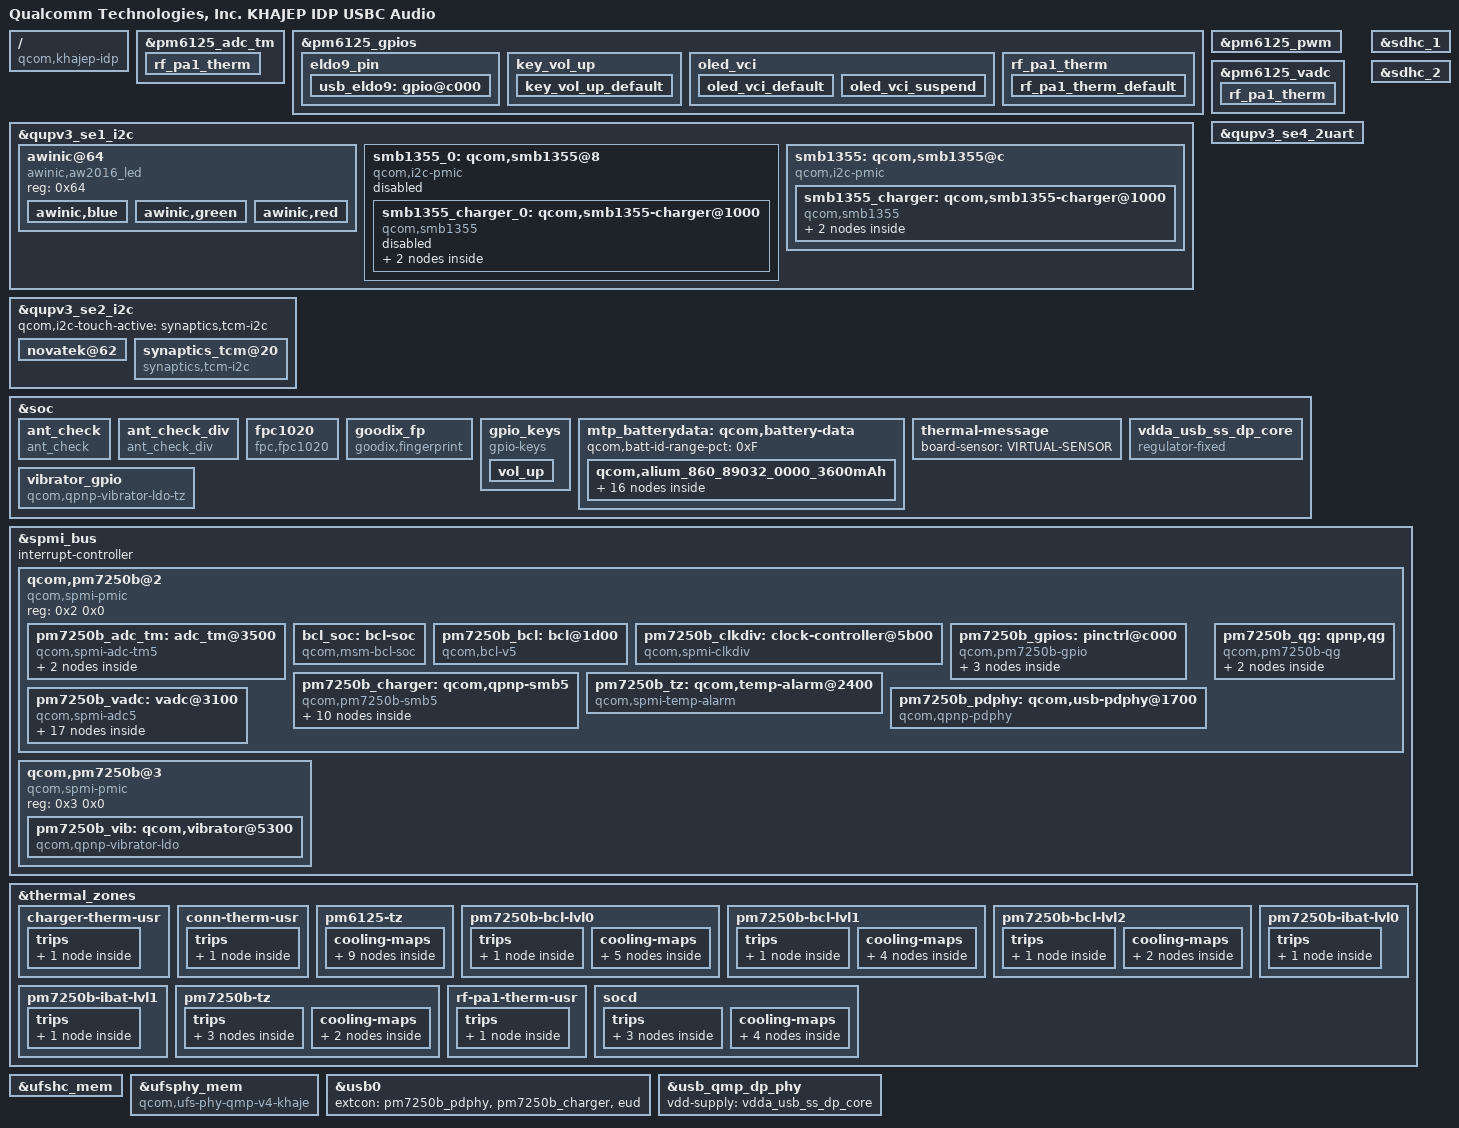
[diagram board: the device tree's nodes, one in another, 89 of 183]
/dts-v1/;
// version: 17
// last_comp_version: 16
// boot_cpuid_phys: 0x0

/ {
    compatible = "qcom,khajep-idp", "qcom,khajep", "qcom,idp";
    model = "Qualcomm Technologies, Inc. KHAJEP IDP USBC Audio";
    qcom,board-id = <0x1010022 0x0>;
    qcom,msm-id = <0x231 0x10000>;
    qcom,pmic-id = <0x2D 0x2E 0x0 0x0>;
};

&pm6125_adc_tm {
    status = "ok";
    rf_pa1_therm {
        io-channels = <&pm6125_vadc 0x55>;
        qcom,hw-settle-time-us = <0xC8>;
        qcom,ratiometric;
        reg = <0x3>;
    };
};

&pm6125_gpios {
    eldo9_pin {
        usb_eldo9: gpio@c000 {
            bias-disable;
            function = "normal";
            output-high;
            pins = "gpio1";
            power-source = <0x0>;
            qcom,drive-strength = <0x2>;
        };
    };
    key_vol_up {
        key_vol_up_default: key_vol_up_default {
            bias-pull-up;
            function = "normal";
            input-enable;
            pins = "gpio5";
            power-source = <0x0>;
        };
    };
    oled_vci {
        oled_vci_default: oled_vci_default {
            bias-disable;
            function = "normal";
            input-disable;
            output-high;
            pins = "gpio9";
            power-source = <0x0>;
            qcom,drive-strength = <0x2>;
        };
        oled_vci_suspend: oled_vci_suspend {
            bias-disable;
            function = "normal";
            input-disable;
            output-low;
            pins = "gpio9";
            power-source = <0x0>;
            qcom,drive-strength = <0x2>;
        };
    };
    rf_pa1_therm {
        rf_pa1_therm_default: rf_pa1_therm_default {
            bias-high-impedance;
            pins = "gpio7";
        };
    };
};

&pm6125_pwm {
    status = "ok";
};

&pm6125_vadc {
    pinctrl-0 = <&camera_therm_default &emmc_therm_default &rf_pa1_therm_default>;
    rf_pa1_therm {
        label = "rf_pa1_therm";
        qcom,hw-settle-time = <0xC8>;
        qcom,pre-scaling = <0x1 0x1>;
        qcom,ratiometric;
        reg = <0x55>;
    };
};

&qupv3_se1_i2c {
    status = "ok";
    awinic@64 {
        compatible = "awinic,aw2016_led";
        reg = <0x64>;
        awinic,blue {
            awinic,fall-time-ms = <0x6>;
            awinic,hold-time-ms = <0x0>;
            awinic,id = <0x2>;
            awinic,imax = <0x2>;
            awinic,led-current = <0x3>;
            awinic,max-brightness = <0xFF>;
            awinic,name = "blue";
            awinic,off-time-ms = <0x4>;
            awinic,rise-time-ms = <0x6>;
        };
        awinic,green {
            awinic,fall-time-ms = <0x6>;
            awinic,hold-time-ms = <0x0>;
            awinic,id = <0x1>;
            awinic,imax = <0x2>;
            awinic,led-current = <0x3>;
            awinic,max-brightness = <0xFF>;
            awinic,name = "green";
            awinic,off-time-ms = <0x4>;
            awinic,rise-time-ms = <0x6>;
        };
        awinic,red {
            awinic,fall-time-ms = <0x6>;
            awinic,hold-time-ms = <0x0>;
            awinic,id = <0x0>;
            awinic,imax = <0x2>;
            awinic,led-current = <0x3>;
            awinic,max-brightness = <0xFF>;
            awinic,name = "red";
            awinic,off-time-ms = <0x4>;
            awinic,rise-time-ms = <0x6>;
        };
    };
    smb1355_0: qcom,smb1355@8 {
        #address-cells = <0x1>;
        #interrupt-cells = <0x3>;
        #size-cells = <0x0>;
        compatible = "qcom,i2c-pmic";
        interrupt-controller;
        interrupt-parent = <&spmi_bus>;
        interrupt_names = "smb1355_0";
        interrupts = <0x0 0xD1 0x0 0x8>;
        qcom,periph-map = <0x10 0x12 0x13 0x16>;
        reg = <0x8>;
        status = "disabled";
        smb1355_charger_0: qcom,smb1355-charger@1000 {
            #address-cells = <0x1>;
            #size-cells = <0x1>;
            compatible = "qcom,smb1355";
            interrupt-parent = <&smb1355_0>;
            reg = <0x1000>;
            status = "disabled";
            qcom,chgr-misc@1600 {
                interrupt-names = "wdog-bark", "temperature-change";
                interrupts = <0x16 0x1 0x1 0x16 0x6 0x1>;
                reg = <0x1600>;
            };
            qcom,chgr@1000 {
                interrupt-names = "chg-state-change";
                interrupts = <0x10 0x1 0x1>;
                reg = <0x1000>;
            };
        };
    };
    smb1355: qcom,smb1355@c {
        #address-cells = <0x1>;
        #interrupt-cells = <0x3>;
        #size-cells = <0x0>;
        compatible = "qcom,i2c-pmic";
        interrupt-controller;
        interrupt-parent = <&spmi_bus>;
        interrupt_names = "smb1355";
        interrupts = <0x2 0xC5 0x0 0x8>;
        pinctrl-0 = <&pm7250b_smb_int_default>;
        pinctrl-names = "default";
        qcom,periph-map = <0x10 0x12 0x13 0x16>;
        reg = <0xC>;
        status = "ok";
        smb1355_charger: qcom,smb1355-charger@1000 {
            #address-cells = <0x1>;
            #size-cells = <0x1>;
            compatible = "qcom,smb1355";
            interrupt-parent = <&smb1355>;
            qcom,hw-die-temp-mitigation;
            qcom,parallel-mode = <0x1>;
            reg = <0x1000>;
            status = "ok";
            qcom,chgr-misc@1600 {
                interrupt-names = "wdog-bark", "temperature-change";
                interrupts = <0x16 0x1 0x1 0x16 0x6 0x1>;
                reg = <0x1600>;
            };
            qcom,chgr@1000 {
                interrupt-names = "chg-state-change";
                interrupts = <0x10 0x1 0x1>;
                reg = <0x1000>;
            };
        };
    };
};

&qupv3_se2_i2c {
    qcom,i2c-touch-active = "synaptics,tcm-i2c";
    status = "okay";
    novatek@62 {
        interrupt-parent = <&tlmm>;
        interrupts = <0x50 0x2008>;
        novatek,irq-gpio = <&tlmm 0x50 0x2008>;
        novatek,reset-gpio = <&tlmm 0x56 0x0>;
        pinctrl-0 = <&ts_int_active &ts_reset_active>;
        pinctrl-1 = <&ts_int_suspend &ts_reset_suspend>;
        pinctrl-2 = <&ts_release>;
        pinctrl-names = "pmx_ts_active", "pmx_ts_suspend", "pmx_ts_release";
        reg = <0x62>;
        status = "ok";
    };
    synaptics_tcm@20 {
        compatible = "synaptics,tcm-i2c";
        interrupt-parent = <&tlmm>;
        interrupts = <0x50 0x2008>;
        pinctrl-0 = <&ts_int_active &ts_reset_active>;
        pinctrl-1 = <&ts_int_suspend &ts_reset_suspend>;
        pinctrl-2 = <&ts_release>;
        pinctrl-names = "pmx_ts_active", "pmx_ts_suspend", "pmx_ts_release";
        reg = <0x20>;
        synaptics,extend_report;
        synaptics,firmware-name = "synaptics_firmware_k.img";
        synaptics,irq-gpio = <&tlmm 0x50 0x2008>;
        synaptics,irq-on-state = <0x0>;
        synaptics,power-delay-ms = <0xC8>;
        synaptics,reset-active-ms = <0x14>;
        synaptics,reset-delay-ms = <0xC8>;
        synaptics,reset-gpio = <&tlmm 0x56 0x0>;
        synaptics,reset-on-state = <0x0>;
        synaptics,ubl-i2c-addr = <0x20>;
    };
};

&qupv3_se4_2uart {
    status = "ok";
};

&sdhc_1 {
    pinctrl-0 = <&sdc1_on>;
    pinctrl-1 = <&sdc1_off>;
    pinctrl-names = "default", "sleep";
    qcom,vdd-current-level = <0x0 0x8B290>;
    qcom,vdd-io-always-on;
    qcom,vdd-io-current-level = <0x0 0x4F588>;
    qcom,vdd-io-lpm-sup;
    qcom,vdd-io-voltage-level = <0x1B7740 0x1B7740>;
    qcom,vdd-voltage-level = <0x2D2A80 0x2D2A80>;
    status = "ok";
    vdd-io-supply = <&L11A>;
    vdd-supply = <&L24A>;
};

&sdhc_2 {
    cd-gpios = <&tlmm 0x58 0x1>;
    pinctrl-0 = <&sdc2_on>;
    pinctrl-1 = <&sdc2_off>;
    pinctrl-names = "default", "sleep";
    qcom,vdd-current-level = <0x0 0xC3500>;
    qcom,vdd-io-bias-current-level = <0x0 0x1770>;
    qcom,vdd-io-bias-voltage-level = <0x132A40 0x132A40>;
    qcom,vdd-io-current-level = <0x0 0x55F0>;
    qcom,vdd-io-voltage-level = <0x1B7740 0x2D2A80>;
    qcom,vdd-voltage-level = <0x2D2A80 0x2D2A80>;
    status = "ok";
    vdd-io-bias-supply = <&L7A>;
    vdd-io-supply = <&L5A>;
    vdd-supply = <&L22A>;
};

&soc {
    ant_check {
        ant_check_gpio = <&tlmm 0x6B 0x0>;
        compatible = "ant_check";
        interrupt-parent = <&tlmm>;
        pinctrl-0 = <&ant_check_default>;
        pinctrl-names = "default";
    };
    ant_check_div {
        ant_check_div_gpio = <&tlmm 0x19 0x0>;
        compatible = "ant_check_div";
        interrupt-parent = <&tlmm>;
        pinctrl-0 = <&ant_check_div_default>;
        pinctrl-names = "default";
    };
    fpc1020 {
        compatible = "fpc,fpc1020";
        fpc,enable-on-boot;
        fpc,gpio_irq = <&tlmm 0x53 0x0>;
        fpc,gpio_rst = <&tlmm 0x68 0x0>;
        fpc,gpio_vdd_for_plsensor = <&tlmm 0x41 0x0>;
        interrupt-parent = <&tlmm>;
        interrupts = <0x53 0x0>;
        pinctrl-0 = <&msm_gpio_104>;
        pinctrl-1 = <&msm_gpio_104_output_high>;
        pinctrl-2 = <&msm_gpio_83>;
        pinctrl-names = "fpc1020_reset_reset", "fpc1020_reset_active", "fpc1020_irq_active";
        status = "ok";
        vcc_spi-supply = <&pm6125_l9>;
        vdd_ana-supply = <&pm6125_l9>;
        vdd_io-supply = <&pm6125_l9>;
    };
    goodix_fp {
        compatible = "goodix,fingerprint";
        fp-gpio-irq = <&tlmm 0x53 0x0>;
        fp-gpio-pwr = <&tlmm 0x41 0x0>;
        fp-gpio-reset = <&tlmm 0x68 0x0>;
        interrupt = <0x53 0x0>;
        interrupt-parent = <&tlmm>;
        pinctrl-0 = <&msm_gpio_104>;
        pinctrl-1 = <&msm_gpio_104_output_high>;
        pinctrl-2 = <&msm_gpio_65>;
        pinctrl-3 = <&msm_gpio_65_output_high>;
        pinctrl-names = "goodix_reset_outputlow", "goodix_reset_outputhigh", "goodix_pwr_outputlow", "goodix_pwr_outputhigh";
        status = "okay";
        vcc_ana_supply = <&pm6125_l9>;
        vcc_spi_supply = <&pm6125_l9>;
        vdd_io-supply = <&pm6125_l9>;
    };
    gpio_keys {
        compatible = "gpio-keys";
        label = "gpio-keys";
        pinctrl-0 = <&key_vol_up_default>;
        pinctrl-names = "default";
        vol_up {
            debounce-interval = <0xF>;
            gpio-key,wakeup;
            gpios = <&pm6125_gpios 0x5 0x1>;
            label = "volume_up";
            linux,can-disable;
            linux,code = <0x73>;
            linux,input-type = <0x1>;
        };
    };
    mtp_batterydata: qcom,battery-data {
        qcom,batt-id-range-pct = <0xF>;
        qcom,alium_860_89032_0000_3600mAh {
            qcom,batt-id-kohm = <0x6B>;
            qcom,battery-beta = <0x109A>;
            qcom,battery-therm-kohm = <0x64>;
            qcom,battery-type = "Alium_860_89032_0000_3600mAh_Jun15th2018";
            qcom,fastchg-current-ma = <0x1518>;
            qcom,fg-cc-cv-threshold-uv = <0x423920>;
            qcom,jeita-fcc-ranges = <0x0 0x32 0x2625A0 0x33 0x190 0x5265C0 0x191 0x1C2 0x2625A0>;
            qcom,jeita-fv-ranges = <0x0 0x32 0x40D990 0x33 0x190 0x426030 0x191 0x1C2 0x40D990>;
            qcom,jeita-hard-thresholds = <0x58CD 0x20B8>;
            qcom,jeita-soft-fcc-ua = <0x2625A0 0x2625A0>;
            qcom,jeita-soft-fv-uv = <0x40D990 0x40D990>;
            qcom,jeita-soft-hys-thresholds = <0x4F5E 0x2943>;
            qcom,jeita-soft-thresholds = <0x5314 0x25E3>;
            qcom,max-voltage-uv = <0x426030>;
            qcom,ocv-based-step-chg;
            qcom,qg-batt-profile-ver = <0x64>;
            qcom,step-chg-ranges = <0x36EE80 0x39FBC0 0x5265C0 0x39FBC1 0x419CE0 0x36EE80 0x419CE1 0x426030 0x2625A0>;
            qcom,fcc1-temp-lut {
                qcom,lut-col-legend = <0x0 0xA 0x19 0x28 0x32>;
                qcom,lut-data = <0xD62 0xDBF 0xDFD 0xE1D 0xE2E>;
            };
            qcom,fcc2-temp-lut {
                qcom,lut-col-legend = <0xFFFFFFF6 0x0 0xA 0x19 0x28 0x32>;
                qcom,lut-data = <0xDDA 0xDF8 0xE02 0xE04 0xDFF 0xDFF>;
            };
            qcom,pc-temp-v1-lut {
                qcom,lut-col-legend = <0x0 0xA 0x19 0x28 0x32>;
                qcom,lut-data = <0xA846 0xA903 0xA965 0xA982 0xA987 0xA757 0xA82C 0xA88B 0xA8B2 0xA8BC 0xA671 0xA747 0xA7A8 0xA7D4 0xA7E5 0xA598 0xA65F 0xA6C5 0xA6F2 0xA707 0xA4CA 0xA582 0xA5E5 0xA611 0xA627 0xA3FF 0xA4AF 0xA508 0xA531 0xA546 0xA330 0xA3E1 0xA430 0xA452 0xA465 0xA25D 0xA311 0xA35C 0xA377 0xA387 0xA1A0 0xA23E 0xA287 0xA29E 0xA2AD 0xA10A 0xA17A 0xA1B1 0xA1C4 0xA1D2 0xA07E 0xA0E5 0xA0F6 0xA0F5 0xA0FC 0x9FA9 0xA061 0xA067 0xA048 0xA036 0x9E4B 0x9F9A 0x9FD6 0x9FAE 0x9F81 0x9CDB 0x9E3D 0x9EE8 0x9EE6 0x9EBF 0x9BED 0x9CD1 0x9D85 0x9DC6 0x9DD7 0x9B4D 0x9BF5 0x9C67 0x9CB4 0x9CF4 0x9AD6 0x9B65 0x9BD6 0x9C18 0x9C4A 0x9A75 0x9AF5 0x9B63 0x9BAA 0x9BC5 0x9A1F 0x9A9B 0x9ADE 0x9B13 0x9B23 0x99C4 0x9A41 0x9A3F 0x9A2D 0x9A41 0x9962 0x99C6 0x998A 0x9943 0x9959 0x98FD 0x992A 0x98B8 0x9892 0x98A0 0x9894 0x9882 0x97F4 0x9800 0x9807 0x982B 0x97C6 0x976F 0x9780 0x9781 0x97CB 0x9713 0x970F 0x970C 0x970C 0x9775 0x9697 0x96B5 0x96A2 0x96A2 0x9724 0x963E 0x965A 0x9642 0x963E 0x96DB 0x95FA 0x9603 0x95E9 0x95E1 0x9698 0x95C7 0x95B7 0x9598 0x958B 0x965B 0x959D 0x9571 0x954E 0x953B 0x9627 0x9575 0x9533 0x950C 0x94F4 0x95F8 0x9550 0x94FE 0x94D1 0x94B3 0x95CC 0x952E 0x94CF 0x949B 0x947A 0x95A2 0x9511 0x94A4 0x9465 0x9440 0x9579 0x94F7 0x947F 0x9432 0x9407 0x954F 0x94D6 0x9458 0x93FE 0x93CC 0x9525 0x94B2 0x942F 0x93C6 0x938B 0x94F0 0x9484 0x9402 0x938B 0x9345 0x94A6 0x943E 0x93BF 0x9343 0x92F7 0x944C 0x93DA 0x935F 0x92ED 0x92A2 0x93E6 0x936C 0x92F1 0x9288 0x923F 0x936B 0x92F1 0x9276 0x920E 0x91C6 0x92E1 0x926F 0x91F1 0x9188 0x9141 0x9248 0x91EA 0x9165 0x90FF 0x90BC 0x91CF 0x9176 0x9100 0x909B 0x905B 0x9179 0x9129 0x90C1 0x9060 0x9022 0x9159 0x910E 0x90AB 0x904F 0x9011 0x913E 0x90F9 0x909A 0x903F 0x9001 0x911A 0x90DE 0x907F 0x9020 0x8FDD 0x90AC 0x9070 0x8FF7 0x8F74 0x8F1A 0x8F68 0x8F1C 0x8E9E 0x8E14 0x8DB6 0x8D9D 0x8D55 0x8CD8 0x8C4C 0x8BEB 0x8B59 0x8B10 0x8A94 0x8A02 0x899F 0x8849 0x87FB 0x877D 0x86E5 0x867D 0x836C 0x8325 0x82AA 0x8209 0x8197 0x7530 0x7530 0x7530 0x7530 0x7530>;
                qcom,lut-row-legend = <0x2710 0x2648 0x2580 0x24B8 0x23F0 0x2328 0x2260 0x2198 0x20D0 0x2008 0x1F40 0x1E78 0x1DB0 0x1CE8 0x1C20 0x1B58 0x1A90 0x19C8 0x1900 0x1838 0x1770 0x16A8 0x15E0 0x1518 0x1450 0x1388 0x12C0 0x11F8 0x1130 0x1068 0xFA0 0xED8 0xE10 0xD48 0xC80 0xBB8 0xAF0 0xA28 0x960 0x898 0x7D0 0x708 0x640 0x578 0x4B0 0x3E8 0x384 0x320 0x2BC 0x258 0x1F4 0x190 0x12C 0xC8 0x64 0x0>;
            };
            qcom,pc-temp-v2-lut {
                qcom,lut-col-legend = <0xFFFFFFF6 0x0 0xA 0x19 0x28 0x32>;
                qcom,lut-data = <0xA98D 0xA97E 0xA974 0xA960 0xA92E 0xA910 0xA7FB 0xA83A 0xA854 0xA856 0xA82F 0xA819 0xA6A3 0xA712 0xA747 0xA757 0xA738 0xA728 0xA594 0xA609 0xA64D 0xA665 0xA64A 0xA63C 0xA4C7 0xA51D 0xA566 0xA581 0xA565 0xA558 0xA3F4 0xA43E 0xA489 0xA4A2 0xA484 0xA478 0xA2AF 0xA364 0xA3B3 0xA3C8 0xA3A5 0xA397 0xA162 0xA292 0xA2E4 0xA2F3 0xA2CA 0xA2B9 0xA11A 0xA1C1 0xA210 0xA21B 0xA1EF 0xA1DE 0xA14F 0xA0EA 0xA131 0xA139 0xA110 0xA103 0xA17A 0xA03C 0xA071 0xA077 0xA047 0xA035 0xA046 0x9FD6 0x9FF5 0x9FF5 0x9FB3 0x9F87 0x9D6D 0x9F7F 0x9F85 0x9F81 0x9F2B 0x9EE2 0x9B88 0x9EAB 0x9EA9 0x9EAD 0x9E5E 0x9E1A 0x9A81 0x9C78 0x9CDE 0x9D1E 0x9D16 0x9D22 0x99B8 0x9A96 0x9B46 0x9BD5 0x9BFE 0x9C3F 0x9913 0x99E8 0x9A78 0x9B4D 0x9B70 0x9B9C 0x9887 0x9977 0x99DF 0x9AEB 0x9B04 0x9B0E 0x97F7 0x98F2 0x9948 0x9A53 0x9A64 0x9A58 0x975C 0x9856 0x98B5 0x9965 0x9971 0x9967 0x96C8 0x97B8 0x9827 0x987F 0x9885 0x9883 0x9649 0x9720 0x9799 0x97D3 0x97D8 0x97D6 0x95D8 0x968D 0x9711 0x9743 0x9748 0x9745 0x957D 0x9608 0x9697 0x96C6 0x96CB 0x96C8 0x9533 0x9591 0x9629 0x9658 0x965C 0x9658 0x94F4 0x952A 0x95C3 0x95F3 0x95F6 0x95F1 0x94BC 0x94D6 0x9565 0x9595 0x9598 0x9592 0x948A 0x9491 0x950E 0x953E 0x9540 0x9538 0x9458 0x9459 0x94BD 0x94F0 0x94EF 0x94E6 0x9429 0x942B 0x9471 0x94AA 0x94A5 0x949B 0x93FA 0x9403 0x942C 0x9467 0x9461 0x9456 0x93CB 0x93DC 0x93ED 0x9426 0x9422 0x9418 0x939A 0x93B7 0x93B6 0x93E7 0x93E7 0x93DD 0x9366 0x9390 0x9384 0x93A6 0x93A1 0x9392 0x9330 0x9367 0x935A 0x9364 0x9348 0x932B 0x92F5 0x933C 0x9330 0x9322 0x92EA 0x92BD 0x92B6 0x9309 0x9301 0x92E2 0x9296 0x925D 0x9274 0x92CE 0x92CF 0x92A2 0x9248 0x9208 0x922D 0x9289 0x9294 0x925E 0x91FE 0x91BC 0x91E4 0x9235 0x924A 0x9214 0x91B6 0x9173 0x919A 0x91D4 0x91F2 0x91C0 0x9166 0x9124 0x9151 0x916D 0x918D 0x9158 0x9101 0x90C0 0x910A 0x9104 0x9119 0x90DA 0x9085 0x9045 0x90BE 0x90A5 0x90A4 0x9064 0x9011 0x8FD4 0x9066 0x9055 0x9058 0x9026 0x8FDE 0x8FA3 0x8FF1 0x9009 0x9027 0x900B 0x8FC1 0x8F87 0x8FA0 0x8FD7 0x9010 0x8FF6 0x8FB0 0x8F76 0x8F3A 0x8F9B 0x8FF2 0x8FD7 0x8F94 0x8F5B 0x8E9D 0x8F3C 0x8FA7 0x8F84 0x8F3F 0x8EFC 0x8DBC 0x8E73 0x8ECD 0x8E86 0x8E46 0x8DF2 0x8C72 0x8D0B 0x8D41 0x8CE7 0x8CA5 0x8C4F 0x8A95 0x8B0D 0x8B2A 0x8AD3 0x8A9A 0x8A45 0x87F8 0x8865 0x887D 0x881C 0x87EC 0x879D 0x841A 0x8496 0x84D3 0x8488 0x847E 0x8426 0x7ECA 0x7F24 0x801B 0x8028 0x7F97 0x7EF0 0x6FCB 0x6E6E 0x6D71 0x6D74 0x6D50 0x6D1A>;
                qcom,lut-row-legend = <0x2710 0x2648 0x2580 0x24B8 0x23F0 0x2328 0x2260 0x2198 0x20D0 0x2008 0x1F40 0x1E78 0x1DB0 0x1CE8 0x1C20 0x1B58 0x1A90 0x19C8 0x1900 0x1838 0x1770 0x16A8 0x15E0 0x1518 0x1450 0x1388 0x12C0 0x11F8 0x1130 0x1068 0xFA0 0xED8 0xE10 0xD48 0xC80 0xBB8 0xAF0 0xA28 0x960 0x898 0x7D0 0x708 0x640 0x578 0x4B0 0x3E8 0x384 0x320 0x2BC 0x258 0x1F4 0x190 0x12C 0xC8 0x64 0x0>;
            };
            qcom,pc-temp-y1-lut {
                qcom,lut-col-legend = <0xFFFFFFF6 0x0 0xA 0x19 0x28 0x32>;
                qcom,lut-data = <0x1DAE 0x1A6C 0x17B7 0x1540 0x1467 0x143B 0x1DB4 0x1A6F 0x17C3 0x153F 0x1466 0x143D 0x1DC0 0x1A74 0x17CA 0x153E 0x1466 0x143E 0x1DCD 0x1A7A 0x17CE 0x153C 0x1466 0x1440 0x1DD8 0x1A7E 0x17D0 0x153B 0x1467 0x1441 0x1DDD 0x1A80 0x17D0 0x153A 0x1467 0x1443 0x1DDC 0x1A80 0x17CC 0x153A 0x1468 0x1443 0x1DDA 0x1A80 0x17C6 0x153A 0x146A 0x1444 0x1DD3 0x1A7D 0x17C5 0x153B 0x146C 0x1445 0x1DBC 0x1A76 0x17C8 0x153C 0x146D 0x1446 0x1DAA 0x1A70 0x17CA 0x153D 0x146F 0x1448 0x1DB3 0x1A6E 0x17C6 0x153D 0x1470 0x1449 0x1DC8 0x1A6F 0x17C0 0x153D 0x1472 0x144B 0x1DDC 0x1A74 0x17C1 0x153E 0x1474 0x144D 0x1DF4 0x1A85 0x17D0 0x1545 0x1479 0x1452 0x1E03 0x1A97 0x17DB 0x154D 0x147C 0x1454 0x1DFA 0x1AA4 0x17DF 0x154F 0x147C 0x1455 0x1DE7 0x1AAF 0x17E3 0x1552 0x147D 0x1455 0x1DD8 0x1AB0 0x17E4 0x1554 0x147E 0x1456 0x1DCA 0x1AA1 0x17E2 0x1555 0x1480 0x1459 0x1DC3 0x1A95 0x17E2 0x1558 0x1483 0x145C 0x1DD6 0x1A97 0x17ED 0x155C 0x1487 0x1460 0x1DF9 0x1A9F 0x17FB 0x1560 0x148B 0x1463 0x1E01 0x1AA5 0x17FD 0x1565 0x148E 0x1467 0x1E00 0x1AA8 0x17F8 0x1569 0x1491 0x146A 0x1E04 0x1AAC 0x17F7 0x156D 0x1493 0x146E 0x1E09 0x1AB8 0x1800 0x1571 0x1496 0x1472 0x1E0C 0x1ACC 0x180B 0x1576 0x149A 0x1475 0x1E0A 0x1AD7 0x180E 0x157B 0x149D 0x1478 0x1DF8 0x1ADC 0x1812 0x1581 0x14A0 0x147A 0x1DE0 0x1ADE 0x1817 0x1586 0x14A3 0x147D 0x1DD9 0x1ADB 0x181B 0x158B 0x14A7 0x1480 0x1DDB 0x1AD7 0x181F 0x1590 0x14AA 0x1484 0x1DDD 0x1AD7 0x1820 0x1593 0x14AD 0x1487 0x1DE1 0x1AD5 0x1821 0x1596 0x14B0 0x1489 0x1DE8 0x1AD3 0x1823 0x1599 0x14B2 0x148B 0x1DF7 0x1ADF 0x1827 0x159B 0x14B4 0x148C 0x1E0A 0x1AEF 0x182C 0x159D 0x14B5 0x148D 0x1E0D 0x1AEF 0x1831 0x159E 0x14B5 0x148E 0x1DFF 0x1AE3 0x1835 0x159F 0x14B6 0x148E 0x1DF5 0x1ADF 0x183A 0x15A1 0x14B7 0x148F 0x1DF6 0x1AE5 0x1841 0x15A5 0x14B9 0x1491 0x1DF6 0x1AEB 0x184C 0x15A8 0x14BA 0x1492 0x1DF6 0x1AF2 0x1849 0x15AA 0x14BB 0x1493 0x1DFA 0x1AF8 0x1850 0x15AF 0x14BE 0x1495 0x1E04 0x1B0B 0x1850 0x15B1 0x14BE 0x1496 0x1E09 0x1B08 0x1859 0x15B4 0x14BE 0x1496 0x1E26 0x1B0E 0x1863 0x15B4 0x14BE 0x1496 0x1E37 0x1B0B 0x186B 0x15B6 0x14BF 0x1496 0x1E2C 0x1B1E 0x1867 0x15B9 0x14C2 0x1498 0x1E29 0x1B3F 0x1879 0x15C2 0x14C5 0x149B 0x1E38 0x1B5B 0x1895 0x15D1 0x14CC 0x14A0 0x1E61 0x1B5F 0x18A8 0x15E4 0x14D3 0x14A6 0x1EB6 0x1B7E 0x18CA 0x15F7 0x14DC 0x14AC 0x1EB6 0x1B7E 0x18CA 0x15F7 0x14DC 0x14AC 0x1EB6 0x1B7E 0x18CA 0x15F7 0x14DC 0x14AC>;
                qcom,lut-row-legend = <0x2710 0x2648 0x2580 0x24B8 0x23F0 0x2328 0x2260 0x2198 0x20D0 0x2008 0x1F40 0x1E78 0x1DB0 0x1CE8 0x1C20 0x1B58 0x1A90 0x19C8 0x1900 0x1838 0x1770 0x16A8 0x15E0 0x1518 0x1450 0x1388 0x12C0 0x11F8 0x1130 0x1068 0xFA0 0xED8 0xE10 0xD48 0xC80 0xBB8 0xAF0 0xA28 0x960 0x898 0x7D0 0x708 0x640 0x578 0x4B0 0x3E8 0x384 0x320 0x2BC 0x258 0x1F4 0x190 0x12C 0xC8 0x64 0x0>;
            };
            qcom,pc-temp-y2-lut {
                qcom,lut-col-legend = <0xFFFFFFF6 0x0 0xA 0x19 0x28 0x32>;
                qcom,lut-data = <0x25D6 0x28A1 0x29B8 0x2B2A 0x2B60 0x2C89 0x2638 0x287F 0x299B 0x2B15 0x2B62 0x2C51 0x2674 0x286A 0x297A 0x2AFB 0x2B61 0x2BFC 0x2693 0x285F 0x2959 0x2ADE 0x2B5E 0x2BA2 0x269F 0x285B 0x293D 0x2ABD 0x2B58 0x2B5A 0x26A2 0x285A 0x292B 0x2A9A 0x2B51 0x2B3C 0x266C 0x2867 0x2922 0x2A6D 0x2B48 0x2B43 0x260B 0x287D 0x291B 0x2A3F 0x2B3B 0x2B4E 0x25F2 0x2878 0x2916 0x2A29 0x2B28 0x2B4D 0x25FE 0x283E 0x2912 0x2A1C 0x2B09 0x2B3A 0x2615 0x2814 0x2910 0x2A13 0x2AE5 0x2B24 0x2698 0x2862 0x291A 0x2A04 0x2AB6 0x2AFB 0x2784 0x28EA 0x2933 0x29F0 0x2A85 0x2AC3 0x27BA 0x2909 0x295A 0x29F2 0x2A7A 0x2ABC 0x26D8 0x28F6 0x29A8 0x2A1D 0x2A90 0x2AF0 0x2601 0x28E9 0x29E0 0x2A53 0x2AB0 0x2B19 0x25E5 0x28FF 0x29FA 0x2A91 0x2AEC 0x2B1B 0x25DE 0x2924 0x2A0E 0x2AD0 0x2B33 0x2B18 0x25D8 0x292D 0x2A1D 0x2AEF 0x2B47 0x2B23 0x25D2 0x292C 0x2A2B 0x2AFC 0x2B48 0x2B59 0x25CD 0x2929 0x2A36 0x2B0A 0x2B4A 0x2B9B 0x25CA 0x28F3 0x2A3F 0x2B29 0x2B78 0x2BD9 0x25C8 0x2849 0x2A48 0x2B54 0x2BC0 0x2C13 0x25C6 0x27D1 0x2A4B 0x2B74 0x2BE2 0x2C3D 0x25C3 0x275F 0x2A50 0x2B8F 0x2BF6 0x2C5C 0x25C0 0x271C 0x2A54 0x2BA1 0x2C07 0x2C71 0x25BF 0x270E 0x2A52 0x2BAC 0x2C19 0x2C83 0x25BE 0x2700 0x2A4A 0x2BB0 0x2C2D 0x2C96 0x25BD 0x26ED 0x2A46 0x2BA7 0x2C35 0x2CB5 0x25BC 0x26D4 0x2A44 0x2B8E 0x2C41 0x2CEC 0x25BB 0x26B9 0x2A3F 0x2B80 0x2C4D 0x2D11 0x25BB 0x26A1 0x29E9 0x2B83 0x2C40 0x2D02 0x25BA 0x268B 0x294E 0x2B8F 0x2C2F 0x2CDA 0x25B9 0x2672 0x290B 0x2B9C 0x2C33 0x2CCA 0x25B8 0x2655 0x28FA 0x2B99 0x2C39 0x2CD1 0x25B8 0x263A 0x28EE 0x2B84 0x2C35 0x2CD6 0x25B7 0x2622 0x28E6 0x2B68 0x2C34 0x2CDC 0x25B7 0x2604 0x290B 0x2B59 0x2C39 0x2CE8 0x25B6 0x25EC 0x293C 0x2B5F 0x2C3B 0x2CE7 0x25B6 0x25DE 0x291D 0x2B60 0x2C36 0x2CD1 0x25B6 0x25D4 0x28BA 0x2B5F 0x2C32 0x2CC5 0x25B6 0x25CB 0x289C 0x2B62 0x2C34 0x2CCC 0x25B6 0x25C4 0x28A6 0x2B5D 0x2C32 0x2CCF 0x25B5 0x25BE 0x281B 0x2B46 0x2C13 0x2CC8 0x25B5 0x25BB 0x27D7 0x2B34 0x2C13 0x2CB0 0x25B5 0x25BB 0x27C4 0x2B11 0x2C20 0x2C82 0x25B5 0x25BA 0x2810 0x2B0D 0x2C0A 0x2C51 0x25B5 0x25B9 0x2851 0x2B23 0x2BE8 0x2C48 0x25B5 0x25B8 0x2853 0x2B28 0x2BEF 0x2C50 0x25B4 0x25B8 0x2837 0x2AE6 0x2C1E 0x2C3A 0x25B4 0x25B6 0x2800 0x2ACC 0x2BF7 0x2BFD 0x25B4 0x25B5 0x27BC 0x2AA1 0x2B7E 0x2BA7 0x25B4 0x25B4 0x2786 0x2A49 0x2B0F 0x2B35 0x25B2 0x25B4 0x2773 0x2A1C 0x2A4F 0x2A4A 0x25B2 0x25B4 0x2773 0x2A1C 0x2A4F 0x2A4A 0x25B2 0x25B4 0x2773 0x2A1C 0x2A4F 0x2A4A>;
                qcom,lut-row-legend = <0x2710 0x2648 0x2580 0x24B8 0x23F0 0x2328 0x2260 0x2198 0x20D0 0x2008 0x1F40 0x1E78 0x1DB0 0x1CE8 0x1C20 0x1B58 0x1A90 0x19C8 0x1900 0x1838 0x1770 0x16A8 0x15E0 0x1518 0x1450 0x1388 0x12C0 0x11F8 0x1130 0x1068 0xFA0 0xED8 0xE10 0xD48 0xC80 0xBB8 0xAF0 0xA28 0x960 0x898 0x7D0 0x708 0x640 0x578 0x4B0 0x3E8 0x384 0x320 0x2BC 0x258 0x1F4 0x190 0x12C 0xC8 0x64 0x0>;
            };
            qcom,pc-temp-y3-lut {
                qcom,lut-col-legend = <0xFFFFFFF6 0x0 0xA 0x19 0x28 0x32>;
                qcom,lut-data = <0x347A 0x3456 0x3421 0x33E5 0x33E0 0x33D8 0x356B 0x345F 0x341A 0x33E4 0x33E0 0x33DA 0x35FF 0x346C 0x3416 0x33E3 0x33E0 0x33DB 0x364D 0x3479 0x3416 0x33E3 0x33E0 0x33DD 0x366B 0x3484 0x3418 0x33E3 0x33E0 0x33DE 0x3670 0x3489 0x341C 0x33E5 0x33E0 0x33DE 0x35EC 0x3489 0x3423 0x33E8 0x33E0 0x33DE 0x34FC 0x3488 0x342B 0x33ED 0x33E1 0x33DE 0x34BB 0x348B 0x342E 0x33EF 0x33E1 0x33DE 0x34BA 0x349E 0x342F 0x33F0 0x33E1 0x33DD 0x34BB 0x34AC 0x3430 0x33F0 0x33E1 0x33DD 0x34D3 0x349E 0x343D 0x33F7 0x33E4 0x33DF 0x3504 0x3481 0x3450 0x3401 0x33E9 0x33E2 0x3510 0x3471 0x3451 0x3402 0x33EA 0x33E3 0x34EC 0x3468 0x343B 0x33FE 0x33E8 0x33E2 0x34CC 0x3462 0x3427 0x33FB 0x33E6 0x33E2 0x34D0 0x345F 0x3422 0x33FD 0x33E8 0x33E2 0x34E0 0x345D 0x341F 0x3401 0x33EC 0x33E3 0x34E7 0x345A 0x341B 0x3401 0x33EC 0x33E3 0x34E9 0x3455 0x3416 0x33F9 0x33E7 0x33E0 0x34EA 0x344F 0x3411 0x33F0 0x33E3 0x33DD 0x34EC 0x3445 0x340C 0x33E8 0x33E1 0x33DC 0x34F0 0x3435 0x3407 0x33E3 0x33E0 0x33DB 0x34F5 0x3427 0x3406 0x33E2 0x33DF 0x33DB 0x3500 0x341C 0x3405 0x33E3 0x33DE 0x33DB 0x3512 0x3417 0x3405 0x33E4 0x33DE 0x33DA 0x3525 0x3418 0x3405 0x33E3 0x33DE 0x33DA 0x3539 0x341B 0x3405 0x33E3 0x33DD 0x33DA 0x354F 0x341F 0x3405 0x33E5 0x33DD 0x33DA 0x356B 0x3423 0x3405 0x33E9 0x33DD 0x33D9 0x358D 0x3428 0x3405 0x33EC 0x33DD 0x33D9 0x35B2 0x342D 0x3400 0x33ED 0x33DE 0x33D9 0x35DA 0x3434 0x33F9 0x33EC 0x33DE 0x33DA 0x360A 0x343C 0x33F6 0x33EC 0x33DF 0x33DA 0x3641 0x3449 0x33F7 0x33EA 0x33DE 0x33DA 0x3680 0x3458 0x33F8 0x33E8 0x33DE 0x33D9 0x36C1 0x3468 0x33FB 0x33E6 0x33DE 0x33D9 0x3702 0x347A 0x3402 0x33E4 0x33DD 0x33D9 0x3742 0x3490 0x3408 0x33E3 0x33DD 0x33D9 0x3781 0x34B0 0x340C 0x33E3 0x33DD 0x33D9 0x37C1 0x34DC 0x340F 0x33E3 0x33DD 0x33D9 0x3803 0x3511 0x3415 0x33E3 0x33DE 0x33DA 0x3845 0x3550 0x341E 0x33E3 0x33DE 0x33DA 0x3892 0x35A3 0x3421 0x33E4 0x33DE 0x33DA 0x38EA 0x3613 0x3429 0x33E3 0x33DE 0x33DA 0x390D 0x3642 0x3430 0x33EB 0x33DF 0x33DC 0x393F 0x363E 0x3435 0x33EC 0x33E1 0x33DD 0x395C 0x3658 0x3442 0x33F0 0x33E3 0x33E0 0x398D 0x36B9 0x3451 0x33F2 0x33E2 0x33E0 0x3A0B 0x3718 0x3452 0x33EE 0x33E1 0x33DD 0x3A97 0x37A6 0x345A 0x33F0 0x33E0 0x33DD 0x3B31 0x3888 0x346F 0x33F5 0x33E3 0x33E1 0x3C10 0x3978 0x3492 0x33F9 0x33E6 0x33E4 0x3F2C 0x3A7B 0x34CA 0x3403 0x33EA 0x33E6 0x3F2C 0x3A7B 0x34CA 0x3403 0x33EA 0x33E6 0x3F2C 0x3A7B 0x34CA 0x3403 0x33EA 0x33E6>;
                qcom,lut-row-legend = <0x2710 0x2648 0x2580 0x24B8 0x23F0 0x2328 0x2260 0x2198 0x20D0 0x2008 0x1F40 0x1E78 0x1DB0 0x1CE8 0x1C20 0x1B58 0x1A90 0x19C8 0x1900 0x1838 0x1770 0x16A8 0x15E0 0x1518 0x1450 0x1388 0x12C0 0x11F8 0x1130 0x1068 0xFA0 0xED8 0xE10 0xD48 0xC80 0xBB8 0xAF0 0xA28 0x960 0x898 0x7D0 0x708 0x640 0x578 0x4B0 0x3E8 0x384 0x320 0x2BC 0x258 0x1F4 0x190 0x12C 0xC8 0x64 0x0>;
            };
            qcom,pc-temp-y4-lut {
                qcom,lut-col-legend = <0xFFFFFFF6 0x0 0xA 0x19 0x28 0x32>;
                qcom,lut-data = <0x45B5 0x41D2 0x40F2 0x406D 0x4045 0x4044 0x452B 0x41DB 0x40EF 0x4073 0x4045 0x4042 0x44EB 0x41EB 0x40EF 0x4078 0x4047 0x4041 0x44E9 0x4200 0x40F2 0x407B 0x4048 0x4040 0x4515 0x421B 0x40F7 0x407D 0x404A 0x4040 0x4561 0x4239 0x40FE 0x407E 0x404B 0x4040 0x4627 0x4263 0x4106 0x407C 0x404D 0x4041 0x478B 0x428E 0x4111 0x407A 0x404E 0x4044 0x4914 0x42A4 0x411C 0x407A 0x4051 0x4046 0x4B24 0x42AD 0x4127 0x4081 0x4055 0x4049 0x4C74 0x42BC 0x4138 0x408C 0x405B 0x404D 0x4A3E 0x4407 0x419F 0x409E 0x4069 0x4059 0x4560 0x4626 0x4237 0x40B4 0x407D 0x4068 0x437A 0x4642 0x4251 0x40BD 0x4081 0x406C 0x4347 0x43A8 0x4203 0x40BF 0x407D 0x406B 0x432D 0x41B1 0x41AA 0x40C3 0x407B 0x406A 0x4320 0x41B5 0x416E 0x40EC 0x4091 0x407A 0x430D 0x41E2 0x413B 0x4129 0x40BA 0x4098 0x42EF 0x41ED 0x4117 0x412A 0x40C0 0x409D 0x42B4 0x41C5 0x40FA 0x40D1 0x4094 0x407D 0x4274 0x4198 0x40E3 0x4085 0x4066 0x405B 0x4249 0x4180 0x40D4 0x4078 0x4054 0x404D 0x4228 0x416E 0x40C8 0x4072 0x4049 0x4043 0x421F 0x416B 0x40C2 0x406F 0x4048 0x4042 0x4223 0x415F 0x40BE 0x406B 0x4048 0x4042 0x422B 0x414F 0x40BB 0x4069 0x4049 0x4043 0x4231 0x4143 0x40BA 0x406B 0x404B 0x4045 0x423B 0x4137 0x40BA 0x406D 0x404E 0x4048 0x4246 0x4136 0x40B9 0x406E 0x4051 0x404C 0x4252 0x4142 0x40B4 0x4070 0x4057 0x4051 0x425E 0x4154 0x40B0 0x4072 0x405E 0x4058 0x426A 0x4167 0x40B4 0x4074 0x4068 0x4063 0x4276 0x417F 0x40BD 0x4076 0x4073 0x4070 0x4283 0x4198 0x40C4 0x4074 0x4075 0x4072 0x4290 0x41B2 0x40C9 0x4069 0x4064 0x4061 0x429C 0x41CD 0x40CD 0x405E 0x404F 0x404C 0x42A8 0x41EF 0x40D2 0x405B 0x4044 0x4043 0x42B5 0x421F 0x40D8 0x4059 0x403E 0x403F 0x42C7 0x4244 0x40DC 0x405A 0x403E 0x4040 0x42E1 0x4252 0x40E9 0x405D 0x4042 0x4045 0x4308 0x425C 0x40FD 0x4060 0x4047 0x404A 0x433B 0x4262 0x410C 0x4063 0x4048 0x404B 0x437E 0x4270 0x4118 0x4064 0x4046 0x4048 0x43D3 0x4287 0x4129 0x4061 0x403D 0x403B 0x442A 0x42C2 0x4147 0x406B 0x4041 0x403E 0x441B 0x42EF 0x4160 0x4075 0x4057 0x405A 0x441E 0x4307 0x4166 0x4084 0x4070 0x4078 0x43ED 0x432A 0x4193 0x40A2 0x4099 0x40A2 0x43D0 0x436E 0x41E6 0x40BE 0x409C 0x4098 0x43E5 0x4383 0x41DE 0x409E 0x406E 0x4064 0x43F6 0x4384 0x41D8 0x409E 0x4060 0x4059 0x4411 0x43A0 0x41FB 0x40BD 0x4070 0x4067 0x4463 0x43F1 0x4266 0x40FB 0x4090 0x4085 0x470A 0x44A2 0x432D 0x41DE 0x4141 0x4118 0x470A 0x44A2 0x432D 0x41DE 0x4141 0x4118 0x470A 0x44A2 0x432D 0x41DE 0x4141 0x4118>;
                qcom,lut-row-legend = <0x2710 0x2648 0x2580 0x24B8 0x23F0 0x2328 0x2260 0x2198 0x20D0 0x2008 0x1F40 0x1E78 0x1DB0 0x1CE8 0x1C20 0x1B58 0x1A90 0x19C8 0x1900 0x1838 0x1770 0x16A8 0x15E0 0x1518 0x1450 0x1388 0x12C0 0x11F8 0x1130 0x1068 0xFA0 0xED8 0xE10 0xD48 0xC80 0xBB8 0xAF0 0xA28 0x960 0x898 0x7D0 0x708 0x640 0x578 0x4B0 0x3E8 0x384 0x320 0x2BC 0x258 0x1F4 0x190 0x12C 0xC8 0x64 0x0>;
            };
            qcom,pc-temp-y5-lut {
                qcom,lut-col-legend = <0xFFFFFFF6 0x0 0xA 0x19 0x28 0x32>;
                qcom,lut-data = <0x2208 0x348A 0x3AB0 0x3545 0x4573 0x3634 0x2208 0x34AA 0x3839 0x3326 0x4393 0x3E82 0x269F 0x34E2 0x3660 0x31DB 0x419B 0x43DA 0x2F8B 0x3522 0x3519 0x3130 0x3FBF 0x46E0 0x3428 0x3557 0x345A 0x30F0 0x3E34 0x4838 0x3590 0x3572 0x341A 0x30E7 0x3D2F 0x4884 0x30EE 0x3576 0x34B3 0x32D3 0x3CA4 0x46C7 0x2869 0x3578 0x35A4 0x35E5 0x3C3F 0x4385 0x267F 0x34B6 0x35C2 0x3648 0x3B81 0x4119 0x2A54 0x3032 0x3545 0x34D0 0x3996 0x3E92 0x2FF6 0x2CF8 0x3494 0x33CF 0x387F 0x3CE5 0x37E1 0x2FD6 0x333D 0x3525 0x3964 0x3CFD 0x4112 0x360E 0x319C 0x3768 0x3ACB 0x3DBD 0x4280 0x3A64 0x326C 0x37DC 0x3B0D 0x3DBF 0x373B 0x3DD4 0x395E 0x3745 0x3A7A 0x3CB2 0x2CF9 0x3F72 0x3ECA 0x36D1 0x3A41 0x3BB0 0x2D03 0x3EC5 0x3F83 0x384B 0x3AE8 0x3B5D 0x2EDC 0x3DC2 0x3FC3 0x3B9D 0x3C38 0x3B2B 0x2F8C 0x3D9A 0x3F92 0x3DC7 0x3E57 0x3B93 0x2F1E 0x3DF3 0x3ECF 0x3F34 0x4225 0x3E9F 0x2E5C 0x3E54 0x3DE6 0x3FC8 0x445B 0x4233 0x2D64 0x3C6D 0x3C08 0x3C17 0x4527 0x44E0 0x2C30 0x3697 0x3971 0x3578 0x4604 0x471B 0x2B6B 0x3248 0x38A0 0x33D2 0x4627 0x47FF 0x2B06 0x2F1A 0x38D8 0x353A 0x4512 0x484D 0x2AD4 0x2D6F 0x3925 0x3660 0x43D2 0x484F 0x2ADD 0x2D4C 0x3975 0x3678 0x4315 0x4790 0x2AEC 0x2D55 0x39CC 0x366C 0x4294 0x45BC 0x2AF3 0x2D44 0x3A34 0x38ED 0x427B 0x43FF 0x2B16 0x2D12 0x3B09 0x40EE 0x4270 0x426F 0x2B4E 0x2D07 0x3BA6 0x465A 0x4280 0x41AA 0x2B80 0x2D07 0x38CB 0x47E5 0x43EF 0x42BB 0x2BA9 0x2CEC 0x3382 0x48DB 0x472C 0x45F6 0x2BD0 0x2CE9 0x319E 0x48B8 0x4A98 0x495F 0x2BF8 0x2D41 0x31A4 0x45BB 0x4E8C 0x4C69 0x2C20 0x2DAA 0x31B5 0x4185 0x51DA 0x4EA9 0x2C45 0x2DD9 0x3221 0x3E14 0x52FB 0x508E 0x2C64 0x2D8A 0x34AF 0x3AEE 0x5257 0x524A 0x2C6C 0x2D32 0x3713 0x3918 0x50BC 0x5292 0x2C5A 0x2D52 0x36DE 0x38BF 0x4E90 0x50E7 0x2C45 0x2D99 0x34F7 0x3913 0x4DBC 0x4F8F 0x2C53 0x2DA9 0x354F 0x3906 0x4EA8 0x5136 0x2CB7 0x2D71 0x370B 0x3898 0x515E 0x56C7 0x2D6C 0x2D2C 0x33CD 0x3962 0x555B 0x5C52 0x2E6E 0x2CC8 0x325A 0x3610 0x4CC2 0x4EA4 0x2FC4 0x2D10 0x320A 0x3E49 0x4394 0x4373 0x30B0 0x2D1B 0x3431 0x3E08 0x42CC 0x40B6 0x322C 0x2E86 0x370E 0x4092 0x40BE 0x3F21 0x3256 0x3099 0x3915 0x3FE1 0x3E27 0x3E5B 0x322C 0x3127 0x38B1 0x3E5F 0x428D 0x410E 0x3117 0x3039 0x38E1 0x4283 0x4414 0x4431 0x2F77 0x2F18 0x37F8 0x4528 0x4741 0x4A06 0x2E6F 0x2E5E 0x37CA 0x4396 0x477B 0x4AB1 0x2B65 0x2D9D 0x3932 0x4343 0x45A6 0x476B 0x2B65 0x2D9D 0x3932 0x4343 0x45A6 0x476B 0x2B65 0x2D9D 0x3932 0x4343 0x45A6 0x476B>;
                qcom,lut-row-legend = <0x2710 0x2648 0x2580 0x24B8 0x23F0 0x2328 0x2260 0x2198 0x20D0 0x2008 0x1F40 0x1E78 0x1DB0 0x1CE8 0x1C20 0x1B58 0x1A90 0x19C8 0x1900 0x1838 0x1770 0x16A8 0x15E0 0x1518 0x1450 0x1388 0x12C0 0x11F8 0x1130 0x1068 0xFA0 0xED8 0xE10 0xD48 0xC80 0xBB8 0xAF0 0xA28 0x960 0x898 0x7D0 0x708 0x640 0x578 0x4B0 0x3E8 0x384 0x320 0x2BC 0x258 0x1F4 0x190 0x12C 0xC8 0x64 0x0>;
            };
            qcom,pc-temp-y6-lut {
                qcom,lut-col-legend = <0xFFFFFFF6 0x0 0xA 0x19 0x28 0x32>;
                qcom,lut-data = <0x1AF4 0x1607 0x1492 0x13C9 0x139D 0x1392 0x1AFB 0x160E 0x148D 0x13C8 0x139D 0x1393 0x1AFF 0x1616 0x148A 0x13C7 0x139D 0x1394 0x1AFF 0x161E 0x148A 0x13C8 0x139D 0x1395 0x1AFC 0x1626 0x148C 0x13C9 0x139E 0x1395 0x1AF7 0x162E 0x148E 0x13CA 0x139F 0x1396 0x1AC7 0x1636 0x1494 0x13CC 0x139F 0x1397 0x1A78 0x163E 0x149C 0x13CF 0x13A1 0x1397 0x1A74 0x1646 0x14A1 0x13D2 0x13A2 0x1398 0x1AFF 0x164C 0x14A3 0x13D4 0x13A3 0x1399 0x1B70 0x1657 0x14A8 0x13D7 0x13A5 0x139A 0x1AF4 0x16AC 0x14CC 0x13E2 0x13AC 0x139F 0x19D3 0x172C 0x1503 0x13EF 0x13B5 0x13A6 0x1941 0x172C 0x150B 0x13F2 0x13B7 0x13A8 0x190E 0x1670 0x14E5 0x13F1 0x13B5 0x13A7 0x18F6 0x15E2 0x14BE 0x13F0 0x13B3 0x13A7 0x18FB 0x15E4 0x14AB 0x13FD 0x13BB 0x13AC 0x1909 0x15F5 0x149C 0x1412 0x13C9 0x13B5 0x190D 0x15F9 0x148F 0x1412 0x13CB 0x13B7 0x190C 0x15ED 0x1483 0x13F3 0x13BB 0x13AB 0x190A 0x15E0 0x147A 0x13D6 0x13AB 0x139F 0x190D 0x15D6 0x1473 0x13CD 0x13A4 0x139A 0x191A 0x15CE 0x146E 0x13C8 0x13A1 0x1397 0x192C 0x15C9 0x146D 0x13C7 0x13A0 0x1397 0x1945 0x15C7 0x146E 0x13C7 0x13A0 0x1397 0x1964 0x15C6 0x146F 0x13C8 0x13A0 0x1398 0x1982 0x15CB 0x1470 0x13C9 0x13A1 0x1398 0x19A0 0x15D5 0x1473 0x13CA 0x13A2 0x1399 0x19C0 0x15E2 0x1475 0x13CC 0x13A3 0x139A 0x19E6 0x15F3 0x1476 0x13D0 0x13A5 0x139C 0x1A11 0x1607 0x1477 0x13D4 0x13A7 0x139E 0x1A3F 0x161D 0x1478 0x13D6 0x13AB 0x13A2 0x1A72 0x1638 0x1479 0x13D7 0x13AF 0x13A6 0x1AA7 0x1655 0x147B 0x13D6 0x13B0 0x13A7 0x1AE0 0x1676 0x147F 0x13D2 0x13AB 0x13A2 0x1B1C 0x169B 0x1483 0x13CE 0x13A5 0x139C 0x1B59 0x16C6 0x1488 0x13CC 0x13A2 0x139A 0x1B96 0x16F8 0x1490 0x13CB 0x13A0 0x1398 0x1BD4 0x1732 0x149A 0x13CA 0x13A0 0x1399 0x1C13 0x1772 0x14A5 0x13CB 0x13A1 0x139A 0x1C51 0x17BC 0x14B0 0x13CD 0x13A3 0x139C 0x1C90 0x1811 0x14BF 0x13CE 0x13A4 0x139D 0x1CD3 0x1875 0x14D0 0x13CF 0x13A3 0x139C 0x1D22 0x18EF 0x14E0 0x13D0 0x13A1 0x1399 0x1D80 0x1984 0x14F9 0x13D2 0x13A3 0x139A 0x1DA5 0x19B9 0x150C 0x13DB 0x13A9 0x13A3 0x1DCF 0x19C4 0x1513 0x13E1 0x13B2 0x13AD 0x1DDE 0x19E7 0x152F 0x13EC 0x13BF 0x13BB 0x1E04 0x1A57 0x155A 0x13F6 0x13C0 0x13B8 0x1E6D 0x1ABF 0x1560 0x13EB 0x13B2 0x13A7 0x1EDF 0x1B41 0x1573 0x13EE 0x13AE 0x13A5 0x1F66 0x1C0D 0x15AB 0x13FD 0x13B6 0x13AC 0x2034 0x1CDF 0x160E 0x1415 0x13C2 0x13B7 0x23C8 0x1DE5 0x16A3 0x1461 0x13F8 0x13E4 0x23C8 0x1DE5 0x16A3 0x1461 0x13F8 0x13E4 0x23C8 0x1DE5 0x16A3 0x1461 0x13F8 0x13E4>;
                qcom,lut-row-legend = <0x2710 0x2648 0x2580 0x24B8 0x23F0 0x2328 0x2260 0x2198 0x20D0 0x2008 0x1F40 0x1E78 0x1DB0 0x1CE8 0x1C20 0x1B58 0x1A90 0x19C8 0x1900 0x1838 0x1770 0x16A8 0x15E0 0x1518 0x1450 0x1388 0x12C0 0x11F8 0x1130 0x1068 0xFA0 0xED8 0xE10 0xD48 0xC80 0xBB8 0xAF0 0xA28 0x960 0x898 0x7D0 0x708 0x640 0x578 0x4B0 0x3E8 0x384 0x320 0x2BC 0x258 0x1F4 0x190 0x12C 0xC8 0x64 0x0>;
            };
            qcom,pc-temp-z1-lut {
                qcom,lut-col-legend = <0x0 0xA 0x19 0x28 0x32>;
                qcom,lut-data = <0x38D1 0x33B6 0x2F09 0x2DA0 0x2D49 0x38BB 0x337F 0x2F0D 0x2D9E 0x2D52 0x38C3 0x3376 0x2F0B 0x2DA5 0x2D5C 0x38C7 0x337E 0x2F07 0x2DA7 0x2D60 0x38D3 0x3382 0x2F03 0x2DA8 0x2D62 0x38EB 0x337D 0x2F01 0x2DA8 0x2D64 0x38FF 0x336C 0x2F02 0x2DA9 0x2D67 0x38F6 0x335E 0x2F03 0x2DAC 0x2D6A 0x38D7 0x335D 0x2F05 0x2DAE 0x2D6D 0x38B6 0x3362 0x2F09 0x2DB1 0x2D6F 0x3896 0x3360 0x2F0D 0x2DB5 0x2D72 0x3874 0x334E 0x2F0F 0x2DB8 0x2D77 0x3843 0x333C 0x2F0F 0x2DBB 0x2D7B 0x3810 0x332E 0x2F0B 0x2DBB 0x2D7C 0x37EE 0x3328 0x2F04 0x2DB9 0x2D7C 0x37D3 0x3329 0x2F01 0x2DB7 0x2D7C 0x37B6 0x3329 0x2F04 0x2DBB 0x2D7F 0x3792 0x332C 0x2F0A 0x2DC2 0x2D85 0x3772 0x3337 0x2F14 0x2DC9 0x2D8B 0x3765 0x3349 0x2F21 0x2DCE 0x2D8F 0x3763 0x335E 0x2F2C 0x2DD3 0x2D93 0x376A 0x3374 0x2F35 0x2DD8 0x2D98 0x3773 0x3384 0x2F3D 0x2DDD 0x2D9C 0x377F 0x338B 0x2F45 0x2DE1 0x2DA1 0x3787 0x3391 0x2F4D 0x2DE7 0x2DA6 0x378C 0x339A 0x2F54 0x2DEC 0x2DAA 0x378F 0x33A6 0x2F5B 0x2DF0 0x2DAF 0x3794 0x33AD 0x2F62 0x2DF4 0x2DB3 0x379F 0x33B2 0x2F69 0x2DF8 0x2DB7 0x37AF 0x33BA 0x2F6F 0x2DFC 0x2DBB 0x37C7 0x33C2 0x2F75 0x2E00 0x2DBF 0x37DE 0x33C9 0x2F7A 0x2E04 0x2DC4 0x37E6 0x33D1 0x2F80 0x2E08 0x2DC8 0x37EA 0x33DE 0x2F86 0x2E0D 0x2DCD 0x37F0 0x33F1 0x2F8E 0x2E12 0x2DD1 0x3807 0x3403 0x2F95 0x2E17 0x2DD5 0x383B 0x3415 0x2F9D 0x2E1A 0x2DD8 0x386B 0x3422 0x2FA5 0x2E1C 0x2DDA 0x3891 0x3427 0x2FAA 0x2E1F 0x2DDC 0x38B0 0x3429 0x2FAD 0x2E21 0x2DDD 0x38B2 0x342D 0x2FB1 0x2E23 0x2DDE 0x3888 0x3439 0x2FB9 0x2E25 0x2DE0 0x3873 0x3448 0x2FBF 0x2E27 0x2DE1 0x386E 0x3457 0x2FC0 0x2E28 0x2DE2 0x3861 0x3449 0x2FC4 0x2E29 0x2DE2 0x386F 0x3454 0x2FC7 0x2E2B 0x2DE2 0x3869 0x3454 0x2FC8 0x2E2B 0x2DE1 0x3868 0x345B 0x2FC9 0x2E2B 0x2DE2 0x385F 0x3457 0x2FCF 0x2E2C 0x2DE3 0x387C 0x3452 0x2FD1 0x2E30 0x2DE6 0x3886 0x346F 0x2FDB 0x2E36 0x2DEB 0x38AA 0x3476 0x2FF3 0x2E3F 0x2DF0 0x3895 0x349E 0x3007 0x2E4A 0x2DFA 0x38D0 0x34C8 0x3032 0x2E5C 0x2E06 0x38D0 0x34C8 0x3032 0x2E5C 0x2E06 0x38D0 0x34C8 0x3032 0x2E5C 0x2E06>;
                qcom,lut-row-legend = <0x2710 0x2648 0x2580 0x24B8 0x23F0 0x2328 0x2260 0x2198 0x20D0 0x2008 0x1F40 0x1E78 0x1DB0 0x1CE8 0x1C20 0x1B58 0x1A90 0x19C8 0x1900 0x1838 0x1770 0x16A8 0x15E0 0x1518 0x1450 0x1388 0x12C0 0x11F8 0x1130 0x1068 0xFA0 0xED8 0xE10 0xD48 0xC80 0xBB8 0xAF0 0xA28 0x960 0x898 0x7D0 0x708 0x640 0x578 0x4B0 0x3E8 0x384 0x320 0x2BC 0x258 0x1F4 0x190 0x12C 0xC8 0x64 0x0>;
            };
            qcom,pc-temp-z2-lut {
                qcom,lut-col-legend = <0x0 0xA 0x19 0x28 0x32>;
                qcom,lut-data = <0x2BB8 0x2632 0x2811 0x296B 0x2A9E 0x280D 0x2A3D 0x2824 0x28FA 0x293E 0x25FE 0x2926 0x282F 0x28BC 0x28C4 0x2606 0x274D 0x282A 0x28AD 0x28AC 0x2620 0x26D2 0x281D 0x2898 0x28A6 0x262F 0x26C3 0x2815 0x288C 0x28A4 0x2631 0x26B5 0x2811 0x2887 0x28A8 0x262C 0x26AA 0x2812 0x2882 0x28AC 0x2625 0x26A2 0x2816 0x2880 0x28AC 0x261B 0x269C 0x2819 0x2884 0x28B5 0x2612 0x2698 0x2813 0x2887 0x28CC 0x2616 0x2696 0x27F3 0x288E 0x28D4 0x2626 0x2699 0x27D7 0x28AE 0x28D3 0x262C 0x26A7 0x27E8 0x28BD 0x28D4 0x2618 0x26B3 0x2814 0x289F 0x28D2 0x25F5 0x26B6 0x282A 0x2883 0x28C7 0x25E5 0x26BA 0x2827 0x288F 0x28D1 0x25E1 0x26C3 0x281D 0x28B2 0x290A 0x25DD 0x26DD 0x2837 0x28E1 0x2937 0x25D6 0x26FD 0x2894 0x2931 0x293F 0x25C9 0x271E 0x28CE 0x296A 0x293F 0x25BE 0x2742 0x28B3 0x2939 0x2923 0x25B7 0x2760 0x2883 0x28BD 0x28EE 0x25B1 0x2775 0x2863 0x288B 0x28CC 0x259F 0x2784 0x284C 0x289E 0x28B4 0x2574 0x278C 0x283F 0x28B6 0x28A5 0x2552 0x2793 0x283C 0x28A9 0x28A6 0x2544 0x2797 0x283D 0x2890 0x28AF 0x250B 0x2796 0x2845 0x2888 0x28BA 0x24D2 0x2793 0x2859 0x2888 0x28CD 0x24C0 0x2792 0x286F 0x288C 0x28E8 0x24B3 0x2793 0x2885 0x289F 0x290A 0x24AA 0x2795 0x289C 0x28C5 0x2934 0x24A2 0x2799 0x28B4 0x28EA 0x2962 0x249C 0x27A2 0x28CE 0x290A 0x299B 0x2498 0x27AA 0x28DF 0x2925 0x29C7 0x249E 0x27B2 0x28E4 0x293C 0x29D8 0x24A4 0x27B7 0x28E7 0x2954 0x29E2 0x24AD 0x27BB 0x28EF 0x2961 0x29ED 0x24B6 0x27C0 0x28FB 0x2964 0x29F9 0x24B5 0x27C2 0x2901 0x2965 0x2A01 0x24A8 0x27B9 0x28FA 0x2971 0x2A03 0x24A4 0x279C 0x28F3 0x2981 0x2A07 0x24AA 0x26EC 0x28F1 0x2987 0x2A1D 0x246C 0x26C6 0x28D6 0x2992 0x2A3B 0x2459 0x26CC 0x28C6 0x29AD 0x2A38 0x2447 0x26DC 0x28DF 0x29C9 0x2A6A 0x2449 0x26CD 0x293D 0x29CA 0x2A89 0x243A 0x26ED 0x297E 0x2A06 0x2AA5 0x243E 0x26C3 0x2925 0x29D7 0x2A55 0x2464 0x269C 0x28DE 0x298A 0x29C5 0x246E 0x264F 0x28B9 0x2971 0x29AF 0x2445 0x25FC 0x289B 0x2927 0x295F 0x241D 0x258F 0x282D 0x28DA 0x2904 0x241D 0x258F 0x282D 0x28DA 0x2904 0x241D 0x258F 0x282D 0x28DA 0x2904>;
                qcom,lut-row-legend = <0x2710 0x2648 0x2580 0x24B8 0x23F0 0x2328 0x2260 0x2198 0x20D0 0x2008 0x1F40 0x1E78 0x1DB0 0x1CE8 0x1C20 0x1B58 0x1A90 0x19C8 0x1900 0x1838 0x1770 0x16A8 0x15E0 0x1518 0x1450 0x1388 0x12C0 0x11F8 0x1130 0x1068 0xFA0 0xED8 0xE10 0xD48 0xC80 0xBB8 0xAF0 0xA28 0x960 0x898 0x7D0 0x708 0x640 0x578 0x4B0 0x3E8 0x384 0x320 0x2BC 0x258 0x1F4 0x190 0x12C 0xC8 0x64 0x0>;
            };
            qcom,pc-temp-z3-lut {
                qcom,lut-col-legend = <0x0 0xA 0x19 0x28 0x32>;
                qcom,lut-data = <0x4C45 0x4BE7 0x4BAD 0x4BB7 0x4B9B 0x4D48 0x4C26 0x4BD0 0x4BAA 0x4B96 0x4DD0 0x4C76 0x4BEE 0x4BAC 0x4B97 0x4DE1 0x4CC3 0x4BFA 0x4BB4 0x4B9C 0x4DCE 0x4CD9 0x4BFF 0x4BB6 0x4B9F 0x4DB7 0x4CDC 0x4C00 0x4BB7 0x4BA2 0x4DAC 0x4CDD 0x4BFE 0x4BB5 0x4BA2 0x4DA7 0x4CDD 0x4BFB 0x4BB0 0x4B9F 0x4DA5 0x4CE0 0x4BF8 0x4BAC 0x4B9B 0x4DA2 0x4CE2 0x4BF6 0x4BAC 0x4B99 0x4DA0 0x4CD4 0x4BF0 0x4BAC 0x4B98 0x4DA5 0x4CAC 0x4BDF 0x4BA7 0x4B98 0x4DB6 0x4C9A 0x4BC8 0x4B9B 0x4B95 0x4DC5 0x4CB6 0x4BCE 0x4B96 0x4B91 0x4DB4 0x4CD7 0x4BEF 0x4BA3 0x4B93 0x4D83 0x4CD1 0x4C01 0x4BB3 0x4B97 0x4D54 0x4CAC 0x4BEC 0x4BAD 0x4B94 0x4D30 0x4C8A 0x4BD0 0x4B9C 0x4B8A 0x4D0E 0x4C6F 0x4BCF 0x4B98 0x4B87 0x4CF1 0x4C5E 0x4BE1 0x4BA6 0x4B8E 0x4CD8 0x4C62 0x4BEE 0x4BB3 0x4B97 0x4CC6 0x4C75 0x4BEF 0x4BB3 0x4B9D 0x4CBC 0x4C87 0x4BEF 0x4BAE 0x4BA1 0x4CB4 0x4C93 0x4BED 0x4BAD 0x4BA2 0x4CAC 0x4C9C 0x4BEA 0x4BB4 0x4BA0 0x4CA3 0x4C9D 0x4BE9 0x4BBA 0x4B9E 0x4C97 0x4C9B 0x4BEF 0x4BB7 0x4B9C 0x4C8C 0x4C97 0x4BF5 0x4BB2 0x4B9A 0x4C7F 0x4C91 0x4BF6 0x4BAE 0x4B98 0x4C6F 0x4C8A 0x4BF4 0x4BA9 0x4B96 0x4C5D 0x4C84 0x4BF2 0x4BA5 0x4B94 0x4C4A 0x4C7F 0x4BEF 0x4BA2 0x4B91 0x4C3A 0x4C7A 0x4BEA 0x4BA0 0x4B8E 0x4C2B 0x4C73 0x4BE7 0x4B9F 0x4B8A 0x4C1E 0x4C6B 0x4BE5 0x4B9E 0x4B86 0x4C17 0x4C65 0x4BE2 0x4B9E 0x4B84 0x4C1B 0x4C5F 0x4BDE 0x4B9E 0x4B84 0x4C23 0x4C5A 0x4BDA 0x4B9D 0x4B86 0x4C39 0x4C56 0x4BD7 0x4B9C 0x4B86 0x4C4F 0x4C53 0x4BD6 0x4B97 0x4B83 0x4C46 0x4C4F 0x4BD4 0x4B93 0x4B81 0x4C28 0x4C4A 0x4BD2 0x4B93 0x4B82 0x4C1B 0x4C3F 0x4BD0 0x4B93 0x4B82 0x4C19 0x4BFB 0x4BCC 0x4B93 0x4B83 0x4BAC 0x4BB3 0x4BB6 0x4B90 0x4B7F 0x4B91 0x4B94 0x4BA0 0x4B89 0x4B78 0x4B89 0x4B8C 0x4B9E 0x4B80 0x4B70 0x4B8B 0x4B87 0x4B8E 0x4B7E 0x4B70 0x4B74 0x4B76 0x4B83 0x4B7C 0x4B6D 0x4B78 0x4B75 0x4B98 0x4B87 0x4B7C 0x4BAB 0x4B91 0x4B9B 0x4B8B 0x4B83 0x4BDA 0x4B96 0x4B9D 0x4B8E 0x4B84 0x4BF2 0x4B94 0x4B99 0x4B92 0x4B87 0x4C08 0x4BA0 0x4B9F 0x4B95 0x4B8C 0x4C08 0x4BA0 0x4B9F 0x4B95 0x4B8C 0x4C08 0x4BA0 0x4B9F 0x4B95 0x4B8C>;
                qcom,lut-row-legend = <0x2710 0x2648 0x2580 0x24B8 0x23F0 0x2328 0x2260 0x2198 0x20D0 0x2008 0x1F40 0x1E78 0x1DB0 0x1CE8 0x1C20 0x1B58 0x1A90 0x19C8 0x1900 0x1838 0x1770 0x16A8 0x15E0 0x1518 0x1450 0x1388 0x12C0 0x11F8 0x1130 0x1068 0xFA0 0xED8 0xE10 0xD48 0xC80 0xBB8 0xAF0 0xA28 0x960 0x898 0x7D0 0x708 0x640 0x578 0x4B0 0x3E8 0x384 0x320 0x2BC 0x258 0x1F4 0x190 0x12C 0xC8 0x64 0x0>;
            };
            qcom,pc-temp-z4-lut {
                qcom,lut-col-legend = <0x0 0xA 0x19 0x28 0x32>;
                qcom,lut-data = <0x4001 0x3C8D 0x3A72 0x3978 0x397B 0x40ED 0x3C83 0x3A6F 0x39C6 0x39B9 0x40DA 0x3C60 0x3A4A 0x39D2 0x39C2 0x4086 0x3C0A 0x3A21 0x39C0 0x39B5 0x4000 0x3BA1 0x39FB 0x39A7 0x399E 0x3F71 0x3B4A 0x39DC 0x3990 0x3986 0x3EF7 0x3B02 0x39C2 0x3981 0x3976 0x3E89 0x3ACB 0x39AC 0x3976 0x396C 0x3E16 0x3AA0 0x39A0 0x3970 0x3966 0x3D82 0x3A79 0x399A 0x396D 0x3961 0x3CF4 0x3A50 0x3998 0x396A 0x395D 0x3CC5 0x3A2F 0x3998 0x3965 0x3959 0x3CDB 0x3A29 0x3999 0x395F 0x3951 0x3CF0 0x3A35 0x399D 0x3961 0x394E 0x3CC2 0x3A3C 0x39A2 0x3970 0x395B 0x3C4C 0x3A29 0x39A0 0x397B 0x3968 0x3BEB 0x39FE 0x398C 0x396B 0x395E 0x3BB2 0x39DD 0x3979 0x394D 0x3947 0x3B8D 0x39C9 0x3978 0x394F 0x3946 0x3B7E 0x39BD 0x3982 0x3988 0x3974 0x3B75 0x39BC 0x3996 0x39BA 0x39A6 0x3B71 0x39BF 0x39CA 0x39BE 0x39AB 0x3B75 0x39C9 0x39FE 0x39B9 0x399F 0x3B7B 0x39FA 0x39FE 0x39AE 0x3991 0x3B80 0x3A38 0x39DF 0x3993 0x3982 0x3B85 0x3A46 0x39BF 0x397D 0x3975 0x3B8C 0x3A43 0x39A7 0x3973 0x396C 0x3B92 0x3A3E 0x3994 0x396E 0x3965 0x3B9E 0x3A2F 0x3989 0x3969 0x395F 0x3BAB 0x3A18 0x3982 0x3965 0x395A 0x3BB3 0x3A05 0x397D 0x3962 0x3955 0x3BBA 0x39F5 0x397B 0x395E 0x3951 0x3BBE 0x39E5 0x397A 0x395A 0x394E 0x3BBC 0x39D6 0x3979 0x395A 0x394D 0x3BB5 0x39C8 0x3979 0x395C 0x3950 0x3BA1 0x39BA 0x3978 0x395E 0x3955 0x3B72 0x39AC 0x3976 0x3961 0x395B 0x3B43 0x39A1 0x3973 0x3963 0x3961 0x3AFC 0x399E 0x3970 0x3963 0x3963 0x3ABC 0x399C 0x396D 0x3963 0x3960 0x3AB4 0x3999 0x396A 0x3962 0x395D 0x3ABB 0x3994 0x3967 0x3960 0x395C 0x3AB9 0x3995 0x3962 0x395D 0x395B 0x3AA3 0x39D0 0x395A 0x3959 0x3958 0x3ABD 0x39EB 0x3957 0x394B 0x394C 0x3AC6 0x39F6 0x3953 0x3935 0x3934 0x3ACB 0x39F8 0x394D 0x3931 0x392D 0x3AC3 0x39FA 0x3959 0x3929 0x3920 0x3AD0 0x3A03 0x3961 0x3925 0x391E 0x3AC0 0x39FF 0x394E 0x392E 0x392C 0x3A9B 0x39F7 0x3956 0x3935 0x3930 0x3A8E 0x39FE 0x3959 0x3936 0x3935 0x3A94 0x3A0E 0x3963 0x3937 0x3936 0x3AA9 0x3A1D 0x3967 0x393A 0x3936 0x3AA9 0x3A1D 0x3967 0x393A 0x3936 0x3AA9 0x3A1D 0x3967 0x393A 0x3936>;
                qcom,lut-row-legend = <0x2710 0x2648 0x2580 0x24B8 0x23F0 0x2328 0x2260 0x2198 0x20D0 0x2008 0x1F40 0x1E78 0x1DB0 0x1CE8 0x1C20 0x1B58 0x1A90 0x19C8 0x1900 0x1838 0x1770 0x16A8 0x15E0 0x1518 0x1450 0x1388 0x12C0 0x11F8 0x1130 0x1068 0xFA0 0xED8 0xE10 0xD48 0xC80 0xBB8 0xAF0 0xA28 0x960 0x898 0x7D0 0x708 0x640 0x578 0x4B0 0x3E8 0x384 0x320 0x2BC 0x258 0x1F4 0x190 0x12C 0xC8 0x64 0x0>;
            };
            qcom,pc-temp-z5-lut {
                qcom,lut-col-legend = <0x0 0xA 0x19 0x28 0x32>;
                qcom,lut-data = <0x2B3C 0x2DAA 0x3498 0x4A8D 0x45CC 0x2EF0 0x3052 0x39FB 0x4721 0x484E 0x3117 0x343D 0x3F9F 0x4802 0x4A61 0x31DF 0x385F 0x430E 0x4B83 0x4D9F 0x326A 0x3A69 0x44EC 0x4E02 0x5124 0x32F3 0x3BAB 0x4673 0x5049 0x55E1 0x33C6 0x3CE5 0x4810 0x514C 0x5936 0x34D0 0x3E95 0x49BE 0x511B 0x5A23 0x35DB 0x4119 0x4B35 0x5160 0x5A1D 0x36FA 0x4312 0x4C4C 0x5327 0x5B6B 0x3859 0x42B6 0x4BAD 0x5424 0x5E2C 0x3A2D 0x3F5C 0x45E6 0x5167 0x6138 0x3C44 0x3ED3 0x3EE4 0x49ED 0x6100 0x3D63 0x47A6 0x4250 0x472F 0x5E7D 0x3D9A 0x506D 0x5049 0x50B3 0x5F98 0x3DB5 0x5016 0x57F1 0x5C40 0x639A 0x3DDA 0x4C6D 0x532F 0x5D14 0x64BC 0x3DD6 0x4A75 0x4BB9 0x59B9 0x646C 0x3D86 0x49E6 0x55E6 0x5B90 0x6454 0x3CDC 0x49B6 0x76E4 0x6B24 0x646B 0x3BCD 0x5034 0x875D 0x7705 0x6492 0x3AD1 0x649B 0x78A4 0x6A60 0x5E9C 0x3A04 0x7968 0x6282 0x5014 0x511E 0x3939 0x8C1A 0x56C4 0x4873 0x4BC7 0x3846 0x9A39 0x4FD8 0x5026 0x4D8E 0x3716 0x9AA6 0x4DFB 0x5780 0x5074 0x35E9 0x91DF 0x53C1 0x5AA0 0x53BA 0x34ED 0x87DB 0x5D83 0x5D20 0x57F1 0x33EA 0x7EB5 0x65EB 0x5E8B 0x5CC6 0x32DD 0x764E 0x6EB9 0x601D 0x628A 0x31CA 0x720C 0x75C6 0x61B9 0x67FC 0x30BF 0x6FD5 0x79EB 0x63F1 0x6C9C 0x2FFA 0x6E15 0x7D26 0x6810 0x7085 0x2F5E 0x6C28 0x8068 0x6DC5 0x7165 0x2ED6 0x6A83 0x83D1 0x7653 0x6FDC 0x2E78 0x6A47 0x8529 0x7B5B 0x6E81 0x2EA9 0x6B32 0x8003 0x7ADF 0x6F61 0x2F11 0x6CA0 0x7890 0x796F 0x710E 0x303E 0x6E9B 0x7749 0x7672 0x709C 0x317F 0x7119 0x77A9 0x6CAD 0x6A94 0x3162 0x71BD 0x77DF 0x65CC 0x65F5 0x300B 0x6C45 0x7771 0x66C4 0x66AF 0x2FB0 0x60CD 0x7669 0x680B 0x6789 0x3015 0x4018 0x70B0 0x6813 0x6600 0x2CA4 0x3328 0x596B 0x6764 0x62B7 0x2BBE 0x3022 0x477D 0x6688 0x6215 0x2B68 0x2F70 0x4725 0x57DA 0x5967 0x2B6C 0x2F09 0x3DD8 0x58E5 0x64BE 0x2AB7 0x2DB9 0x398D 0x5BD2 0x6460 0x2AE0 0x2DED 0x457F 0x6BCD 0x75C0 0x2CB0 0x2FF3 0x438F 0x6311 0x7110 0x2D80 0x2FA5 0x439F 0x6129 0x668D 0x2D89 0x2EBE 0x3EC3 0x61E3 0x62CA 0x2D50 0x2E6C 0x3EB4 0x5B72 0x6005 0x2D50 0x2E6C 0x3EB4 0x5B72 0x6005 0x2D50 0x2E6C 0x3EB4 0x5B72 0x6005>;
                qcom,lut-row-legend = <0x2710 0x2648 0x2580 0x24B8 0x23F0 0x2328 0x2260 0x2198 0x20D0 0x2008 0x1F40 0x1E78 0x1DB0 0x1CE8 0x1C20 0x1B58 0x1A90 0x19C8 0x1900 0x1838 0x1770 0x16A8 0x15E0 0x1518 0x1450 0x1388 0x12C0 0x11F8 0x1130 0x1068 0xFA0 0xED8 0xE10 0xD48 0xC80 0xBB8 0xAF0 0xA28 0x960 0x898 0x7D0 0x708 0x640 0x578 0x4B0 0x3E8 0x384 0x320 0x2BC 0x258 0x1F4 0x190 0x12C 0xC8 0x64 0x0>;
            };
            qcom,pc-temp-z6-lut {
                qcom,lut-col-legend = <0x0 0xA 0x19 0x28 0x32>;
                qcom,lut-data = <0x409A 0x3C2E 0x39DD 0x392F 0x3913 0x416D 0x3C48 0x39EE 0x394B 0x392D 0x419B 0x3C57 0x39EE 0x3952 0x3933 0x4181 0x3C50 0x39E4 0x394F 0x3931 0x413B 0x3C33 0x39D5 0x3947 0x392A 0x40E4 0x3C0C 0x39C7 0x393D 0x3921 0x409C 0x3BE5 0x39BB 0x3935 0x391B 0x4062 0x3BCB 0x39B0 0x392E 0x3915 0x4027 0x3BB9 0x39AA 0x392A 0x3910 0x3FE0 0x3BA7 0x39A7 0x3929 0x390E 0x3F9A 0x3B8A 0x39A3 0x3928 0x390C 0x3F73 0x3B64 0x399A 0x3924 0x390B 0x3F65 0x3B56 0x398E 0x391C 0x3906 0x3F55 0x3B62 0x3992 0x3919 0x3903 0x3F1E 0x3B70 0x39A4 0x3927 0x390A 0x3EC0 0x3B64 0x39AC 0x3933 0x3912 0x3E70 0x3B3F 0x3999 0x392A 0x390C 0x3E3A 0x3B22 0x3982 0x3915 0x38FE 0x3E0F 0x3B10 0x3982 0x3914 0x38FC 0x3DF2 0x3B06 0x3991 0x3936 0x3915 0x3DDC 0x3B09 0x39A5 0x3953 0x3930 0x3DD2 0x3B19 0x39C1 0x3956 0x3934 0x3DD2 0x3B2E 0x39D7 0x3953 0x3934 0x3DD7 0x3B4E 0x39D6 0x394F 0x3932 0x3DDC 0x3B6D 0x39C9 0x3948 0x392B 0x3DE1 0x3B75 0x39BE 0x3942 0x3924 0x3DE6 0x3B75 0x39B8 0x393D 0x391F 0x3DEA 0x3B74 0x39B4 0x3938 0x391C 0x3DEE 0x3B6E 0x39B1 0x3935 0x3919 0x3DF0 0x3B64 0x39AE 0x3931 0x3916 0x3DF0 0x3B5C 0x39AB 0x392E 0x3913 0x3DF0 0x3B54 0x39A9 0x392B 0x3910 0x3DEF 0x3B4C 0x39A8 0x3928 0x390D 0x3DED 0x3B46 0x39A7 0x3928 0x390C 0x3DEB 0x3B40 0x39A7 0x3929 0x390C 0x3DEB 0x3B3C 0x39A6 0x392A 0x390C 0x3DED 0x3B38 0x39A4 0x392C 0x390F 0x3DEF 0x3B35 0x39A2 0x392D 0x3913 0x3DEF 0x3B35 0x39A0 0x392D 0x3914 0x3DEE 0x3B36 0x399F 0x392A 0x3912 0x3DEB 0x3B36 0x399E 0x3928 0x3910 0x3DE2 0x3B35 0x399D 0x3927 0x3910 0x3DD8 0x3B34 0x399B 0x3927 0x390F 0x3DCD 0x3B2C 0x3997 0x3926 0x390F 0x3DA1 0x3B16 0x398B 0x391D 0x3908 0x3D94 0x3B10 0x397F 0x3911 0x38F9 0x3D93 0x3B0A 0x397C 0x390A 0x38F2 0x3D8F 0x3B0C 0x3979 0x3906 0x38EC 0x3D8D 0x3B07 0x3977 0x3903 0x38EA 0x3D95 0x3B0C 0x397C 0x390D 0x38F8 0x3DA1 0x3B20 0x3983 0x3914 0x38FF 0x3DBD 0x3B30 0x398C 0x3918 0x3902 0x3DE0 0x3B45 0x3993 0x391D 0x3906 0x3E15 0x3B6D 0x39A2 0x3924 0x390D 0x3E15 0x3B6D 0x39A2 0x3924 0x390D 0x3E15 0x3B6D 0x39A2 0x3924 0x390D>;
                qcom,lut-row-legend = <0x2710 0x2648 0x2580 0x24B8 0x23F0 0x2328 0x2260 0x2198 0x20D0 0x2008 0x1F40 0x1E78 0x1DB0 0x1CE8 0x1C20 0x1B58 0x1A90 0x19C8 0x1900 0x1838 0x1770 0x16A8 0x15E0 0x1518 0x1450 0x1388 0x12C0 0x11F8 0x1130 0x1068 0xFA0 0xED8 0xE10 0xD48 0xC80 0xBB8 0xAF0 0xA28 0x960 0x898 0x7D0 0x708 0x640 0x578 0x4B0 0x3E8 0x384 0x320 0x2BC 0x258 0x1F4 0x190 0x12C 0xC8 0x64 0x0>;
            };
        };
    };
    thermal-message {
        board-sensor = "VIRTUAL-SENSOR";
    };
    vdda_usb_ss_dp_core {
        compatible = "regulator-fixed";
        enable-active-high;
        gpio = <&pm6125_gpios 0x1 0x0>;
        pinctrl-0 = <&usb_eldo9>;
        pinctrl-names = "default";
        regulator-max-microvolt = <0xD6D80>;
        regulator-min-microvolt = <0xD6D80>;
        regulator-name = "vdd_supply";
    };
    vibrator_gpio {
        compatible = "qcom,qpnp-vibrator-ldo-tz";
        pinctrl-0 = <&vib_out_gpio8_default>;
        pinctrl-names = "default";
        status = "ok";
        vib,en-gpio = <&pm6125_gpios 0x8 0x1>;
    };
};

&spmi_bus {
    #address-cells = <0x2>;
    #interrupt-cells = <0x4>;
    #size-cells = <0x0>;
    interrupt-controller;
    qcom,pm7250b@2 {
        #address-cells = <0x1>;
        #size-cells = <0x0>;
        compatible = "qcom,spmi-pmic";
        reg = <0x2 0x0>;
        pm7250b_adc_tm: adc_tm@3500 {
            #address-cells = <0x1>;
            #size-cells = <0x0>;
            #thermal-sensor-cells = <0x1>;
            compatible = "qcom,spmi-adc-tm5";
            interrupt-names = "pm-adc-tm5";
            interrupts = <0x2 0x35 0x0 0x1>;
            reg = <0x3500>;
            status = "ok";
            charger_skin_therm@4d {
                io-channels = <&pm7250b_vadc 0x4D>;
                qcom,hw-settle-time-us = <0xC8>;
                qcom,ratiometric;
                reg = <0x0>;
            };
            conn_therm@4f {
                io-channels = <&pm7250b_vadc 0x4F>;
                qcom,hw-settle-time-us = <0xC8>;
                qcom,ratiometric;
                reg = <0x1>;
            };
        };
        bcl_soc: bcl-soc {
            #thermal-sensor-cells = <0x0>;
            compatible = "qcom,msm-bcl-soc";
        };
        pm7250b_bcl: bcl@1d00 {
            #thermal-sensor-cells = <0x1>;
            compatible = "qcom,bcl-v5";
            interrupt-names = "bcl-lvl0", "bcl-lvl1", "bcl-lvl2";
            interrupts = <0x2 0x1D 0x0 0x0 0x2 0x1D 0x1 0x0 0x2 0x1D 0x2 0x0>;
            reg = <0x1D00>;
        };
        pm7250b_clkdiv: clock-controller@5b00 {
            #clock-cells = <0x1>;
            assigned-clock-rates = <0x124F800>;
            assigned-clocks = <&pm7250b_clkdiv 0x1>;
            clock-names = "xo";
            clock-output-names = "pm7250b_div_clk1";
            clocks = <&rpmcc 0x0>;
            compatible = "qcom,spmi-clkdiv";
            qcom,num-clkdivs = <0x1>;
            reg = <0x5B00>;
        };
        pm7250b_gpios: pinctrl@c000 {
            #gpio-cells = <0x2>;
            #interrupt-cells = <0x2>;
            compatible = "qcom,pm7250b-gpio";
            gpio-controller;
            interrupt-controller;
            reg = <0xC000>;
            disp_lcd_bias_en {
                disp_lcd_bias_en_default: disp_lcd_bias_en_default {
                    bias-disable;
                    function = "func1";
                    input-disable;
                    output-enable;
                    pins = "gpio5";
                    power-source = <0x0>;
                    qcom,drive-strength = <0x2>;
                };
            };
            pm7250b_smb_int_default: pm7250b_smb_int_default {
                bias-pull-up;
                function = "gpio";
                input-enable;
                pins = "gpio6";
                power-source = <0x0>;
                qcom,pull-up-strength = <0x0>;
            };
        };
        pm7250b_charger: qcom,qpnp-smb5 {
            #address-cells = <0x1>;
            #cooling-cells = <0x2>;
            #io-channel-cells = <0x1>;
            #size-cells = <0x1>;
            compatible = "qcom,pm7250b-smb5";
            depends-on-supply = <&pm7250b_vadc>;
            dpdm-supply = <&usb2_phy0>;
            io-channel-names = "usb_in_voltage", "usb_in_current", "chg_temp", "die_temp", "conn_temp", "sbux_res", "vph_voltage", "skin_temp", "resistance_id", "voltage_now", "temp", "capacity", "voltage_ocv", "voltage_avg", "debug_battery", "real_capacity", "cc_soc", "current_now", "voltage_max", "charge_full", "charge_counter", "cycle_count", "charge_full_design", "time_to_full_now";
            io-channels = <&pm7250b_vadc 0x8 &pm7250b_vadc 0x7 &pm7250b_vadc 0x9 &pm7250b_vadc 0x6 &pm7250b_vadc 0x4F &pm7250b_vadc 0x99 &pm7250b_vadc 0x83 &pm7250b_vadc 0x4D &pm7250b_qg 0x4B &pm7250b_qg 0x46 &pm7250b_qg 0x45 &pm7250b_qg 0x42 &pm7250b_qg 0x47 &pm7250b_qg 0x5D &pm7250b_qg 0x4E &pm7250b_qg 0x44 &pm7250b_qg 0x5B &pm7250b_qg 0x48 &pm7250b_qg 0x2D &pm7250b_qg 0x53 &pm7250b_qg 0x49 &pm7250b_qg 0x52 &pm7250b_qg 0x54 &pm7250b_qg 0x56>;
            qcom,auto-recharge-soc = <0x62>;
            qcom,battery-data = <&mtp_batterydata>;
            qcom,charger-temp-max = <0x320>;
            qcom,en-skin-therm-mitigation;
            qcom,fcc-step-delay-ms = <0x64>;
            qcom,fcc-step-size-ua = <0x186A0>;
            qcom,fcc-stepping-enable;
            qcom,hvdcp2-12v-max-icl-ua = <0x16E360>;
            qcom,hvdcp2-max-icl-ua = <0x1E8480>;
            qcom,hvdcp3-standalone-config;
            qcom,sec-charger-config = <0x2>;
            qcom,smb-internal-pull-kohm = <0x0>;
            qcom,smb-temp-max = <0x320>;
            qcom,step-charging-enable;
            qcom,suspend-input-on-debug-batt;
            qcom,sw-jeita-enable;
            qcom,thermal-mitigation = <0x5265C0 0x44AA20 0x3D0900 0x3567E0 0x2DC6C0 0x2625A0 0x1E8480 0x16E360 0xF4240 0x7A120>;
            status = "ok";
            qcom,batif@1200 {
                interrupt-names = "bat-temp", "bat-ov", "bat-low", "bat-therm-or-id-missing", "bat-terminal-missing", "buck-oc", "vph-ov";
                interrupts = <0x2 0x12 0x0 0x1 0x2 0x12 0x2 0x3 0x2 0x12 0x3 0x3 0x2 0x12 0x4 0x3 0x2 0x12 0x5 0x3 0x2 0x12 0x6 0x3 0x2 0x12 0x7 0x3>;
                reg = <0x1200>;
            };
            qcom,chg-sdam@b000 {
                reg = <0xB000>;
            };
            qcom,chgr@1000 {
                interrupt-names = "chgr-error", "chg-state-change", "step-chg-state-change", "step-chg-soc-update-fail", "step-chg-soc-update-req", "fg-fvcal-qualified", "vph-alarm", "vph-drop-prechg";
                interrupts = <0x2 0x10 0x0 0x1 0x2 0x10 0x1 0x1 0x2 0x10 0x2 0x1 0x2 0x10 0x3 0x1 0x2 0x10 0x4 0x1 0x2 0x10 0x5 0x1 0x2 0x10 0x6 0x1 0x2 0x10 0x7 0x1>;
                reg = <0x1000>;
            };
            qcom,dc@1400 {
                interrupt-names = "dcin-vashdn", "dcin-uv", "dcin-ov", "dcin-plugin", "dcin-revi", "dcin-pon", "dcin-en";
                interrupts = <0x2 0x14 0x1 0x3 0x2 0x14 0x2 0x3 0x2 0x14 0x3 0x3 0x2 0x14 0x4 0x3 0x2 0x14 0x5 0x3 0x2 0x14 0x6 0x1 0x2 0x14 0x7 0x1>;
                reg = <0x1400>;
            };
            qcom,dcdc@1100 {
                interrupt-names = "otg-fail", "otg-oc-disable-sw", "otg-oc-hiccup", "bsm-active", "high-duty-cycle", "input-current-limiting", "concurrent-mode-disable", "switcher-power-ok";
                interrupts = <0x2 0x11 0x0 0x1 0x2 0x11 0x1 0x1 0x2 0x11 0x2 0x1 0x2 0x11 0x3 0x3 0x2 0x11 0x4 0x3 0x2 0x11 0x5 0x3 0x2 0x11 0x6 0x1 0x2 0x11 0x7 0x3>;
                reg = <0x1100>;
            };
            qcom,misc@1600 {
                interrupt-names = "wdog-snarl", "wdog-bark", "aicl-fail", "aicl-done", "smb-en", "imp-trigger", "temp-change", "temp-change-smb";
                interrupts = <0x2 0x16 0x0 0x1 0x2 0x16 0x1 0x1 0x2 0x16 0x2 0x1 0x2 0x16 0x3 0x1 0x2 0x16 0x4 0x3 0x2 0x16 0x5 0x1 0x2 0x16 0x6 0x1 0x2 0x16 0x7 0x1>;
                reg = <0x1600>;
            };
            smb5_vbus: qcom,smb5-vbus {
                regulator-name = "smb5-vbus";
            };
            smb5_vconn: qcom,smb5-vconn {
                regulator-name = "smb5-vconn";
            };
            qcom,typec@1500 {
                interrupt-names = "typec-or-rid-detect-change", "typec-vpd-detect", "typec-cc-state-change", "typec-vconn-oc", "typec-vbus-change", "typec-attach-detach", "typec-legacy-cable-detect", "typec-try-snk-src-detect";
                interrupts = <0x2 0x15 0x0 0x1 0x2 0x15 0x1 0x1 0x2 0x15 0x2 0x1 0x2 0x15 0x3 0x1 0x2 0x15 0x4 0x1 0x2 0x15 0x5 0x1 0x2 0x15 0x6 0x1 0x2 0x15 0x7 0x1>;
                reg = <0x1500>;
            };
            qcom,usb@1300 {
                interrupt-names = "usbin-collapse", "usbin-vashdn", "usbin-uv", "usbin-ov", "usbin-plugin", "usbin-revi-change", "usbin-src-change", "usbin-icl-change";
                interrupts = <0x2 0x13 0x0 0x3 0x2 0x13 0x1 0x3 0x2 0x13 0x2 0x3 0x2 0x13 0x3 0x3 0x2 0x13 0x4 0x3 0x2 0x13 0x5 0x3 0x2 0x13 0x6 0x1 0x2 0x13 0x7 0x1>;
                reg = <0x1300>;
            };
        };
        pm7250b_tz: qcom,temp-alarm@2400 {
            #thermal-sensor-cells = <0x0>;
            compatible = "qcom,spmi-temp-alarm";
            interrupts = <0x2 0x24 0x0 0x3>;
            io-channel-names = "thermal";
            io-channels = <&pm7250b_vadc 0x6>;
            qcom,temperature-threshold-set = <0x1>;
            reg = <0x2400>;
        };
        pm7250b_pdphy: qcom,usb-pdphy@1700 {
            #io-channel-cells = <0x1>;
            compatible = "qcom,qpnp-pdphy";
            interrupt-names = "sig-tx", "sig-rx", "msg-tx", "msg-rx", "msg-tx-failed", "msg-tx-discarded", "msg-rx-discarded", "fr-swap";
            interrupts = <0x2 0x17 0x0 0x1 0x2 0x17 0x1 0x1 0x2 0x17 0x2 0x1 0x2 0x17 0x3 0x1 0x2 0x17 0x4 0x1 0x2 0x17 0x5 0x1 0x2 0x17 0x6 0x1 0x2 0x17 0x7 0x1>;
            io-channel-names = "pd_active", "typec_cc_orientation", "connector_type", "typec_power_role", "pd_usb_suspend_supported", "typec_src_rp", "pd_in_hard_reset", "pr_current_max", "pr_swap", "pd_voltage_min", "pd_voltage_max", "real_type", "typec_mode", "pe_start";
            io-channels = <&pm7250b_charger 0x4 &pm7250b_charger 0x3 &pm7250b_charger 0xD &pm7250b_charger 0x2 &pm7250b_charger 0x1F &pm7250b_charger 0x1D &pm7250b_charger 0x1E &pm7250b_charger 0x0 &pm7250b_charger 0x20 &pm7250b_charger 0xC &pm7250b_charger 0xB &pm7250b_charger 0xA &pm7250b_charger 0x1 &pm7250b_charger 0x7>;
            qcom,default-sink-caps = <0x1388 0xBB8 0x2328 0xBB8 0x2EE0 0x8CA>;
            reg = <0x1700>;
            vbus-supply = <&smb5_vbus>;
            vconn-supply = <&smb5_vconn>;
            vdd-pdphy-supply = <&L15A>;
        };
        pm7250b_qg: qpnp,qg {
            #address-cells = <0x1>;
            #io-channel-cells = <0x1>;
            #size-cells = <0x1>;
            compatible = "qcom,pm7250b-qg";
            io-channel-names = "batt-therm", "batt-id", "input_current_limited", "recharge_soc", "force_recharge", "charge_done";
            io-channels = <&pm7250b_vadc 0x4A &pm7250b_vadc 0x4B &pm7250b_charger 0x37 &pm7250b_charger 0x3F &pm7250b_charger 0x40 &pm7250b_charger 0x39>;
            qcom,bass-enable;
            qcom,battery-data = <&mtp_batterydata>;
            qcom,cl-feedback-on;
            qcom,fvss-enable;
            qcom,fvss-vbatt-mv = <0xDAC>;
            qcom,hold-soc-while-full;
            qcom,linearize-soc;
            qcom,qg-iterm-ma = <0x64>;
            qcom,s3-entry-fifo-length = <0x2>;
            qcom,tcss-enable;
            qcom,vbatt-cutoff-mv = <0xD48>;
            qcom,vbatt-empty-cold-mv = <0xC1C>;
            qcom,vbatt-empty-mv = <0xC80>;
            qcom,vbatt-low-cold-mv = <0xED8>;
            qcom,vbatt-low-mv = <0xDAC>;
            status = "ok";
            qcom,qg-sdam@b100 {
                reg = <0xB100>;
                status = "okay";
            };
            qcom,qgauge@4800 {
                interrupt-names = "qg-batt-missing", "qg-vbat-low", "qg-vbat-empty", "qg-fifo-done", "qg-good-ocv";
                interrupts = <0x2 0x48 0x0 0x3 0x2 0x48 0x1 0x3 0x2 0x48 0x2 0x1 0x2 0x48 0x3 0x1 0x2 0x48 0x4 0x1>;
                reg = <0x4800>;
                status = "okay";
            };
        };
        pm7250b_vadc: vadc@3100 {
            #address-cells = <0x1>;
            #io-channel-cells = <0x1>;
            #size-cells = <0x0>;
            compatible = "qcom,spmi-adc5";
            interrupt-names = "eoc-int-en-set";
            interrupts = <0x2 0x31 0x0 0x1>;
            io-channel-ranges;
            qcom,adc-vdd-reference = <0x753>;
            reg = <0x3100>;
            reg-names = "adc5-usr-base";
            bat_id@4b {
                label = "bat_id";
                qcom,hw-settle-time = <0xC8>;
                qcom,pre-scaling = <0x1 0x1>;
                qcom,ratiometric;
                reg = <0x4B>;
            };
            bat_therm@4a {
                label = "bat_therm";
                qcom,hw-settle-time = <0xC8>;
                qcom,pre-scaling = <0x1 0x1>;
                qcom,ratiometric;
                reg = <0x4A>;
            };
            bat_therm_30k@2a {
                label = "bat_therm_30k";
                qcom,hw-settle-time = <0xC8>;
                qcom,pre-scaling = <0x1 0x1>;
                qcom,ratiometric;
                reg = <0x2A>;
            };
            bat_therm_400k@6a {
                label = "bat_therm_400k";
                qcom,hw-settle-time = <0xC8>;
                qcom,pre-scaling = <0x1 0x1>;
                qcom,ratiometric;
                reg = <0x6A>;
            };
            charger_skin_therm@4d {
                label = "charger_skin_therm";
                qcom,hw-settle-time = <0xC8>;
                qcom,pre-scaling = <0x1 0x1>;
                qcom,ratiometric;
                reg = <0x4D>;
            };
            chg_sbux@99 {
                label = "chg_sbux";
                qcom,pre-scaling = <0x1 0x3>;
                reg = <0x99>;
            };
            chg_temp@9 {
                label = "chg_temp";
                qcom,pre-scaling = <0x1 0x1>;
                reg = <0x9>;
            };
            conn_therm@4f {
                label = "conn_therm";
                qcom,hw-settle-time = <0xC8>;
                qcom,pre-scaling = <0x1 0x1>;
                qcom,ratiometric;
                reg = <0x4F>;
            };
            die_temp@2 {
                label = "die_temp";
                qcom,pre-scaling = <0x1 0x1>;
                reg = <0x6>;
            };
            mid_chg_div6@1e {
                label = "chg_mid";
                qcom,pre-scaling = <0x1 0x6>;
                reg = <0x1E>;
            };
            ref_gnd@0 {
                label = "ref_gnd";
                qcom,pre-scaling = <0x1 0x1>;
                reg = <0x0>;
            };
            smb1390_therm@e {
                label = "smb1390_therm";
                qcom,hw-settle-time = <0xC8>;
                qcom,pre-scaling = <0x1 0x1>;
                reg = <0xE>;
            };
            usb_in_i_uv@7 {
                label = "usb_in_i_uv";
                qcom,pre-scaling = <0x1 0x1>;
                reg = <0x7>;
            };
            usb_in_v_div_16@8 {
                label = "usb_in_v_div_16";
                qcom,pre-scaling = <0x1 0x10>;
                reg = <0x8>;
            };
            vbat_sns@84 {
                label = "vbat_sns";
                qcom,pre-scaling = <0x1 0x3>;
                reg = <0x84>;
            };
            vph_pwr@83 {
                label = "vph_pwr";
                qcom,pre-scaling = <0x1 0x3>;
                reg = <0x83>;
            };
            vref_1p25@1 {
                label = "vref_1p25";
                qcom,pre-scaling = <0x1 0x1>;
                reg = <0x1>;
            };
        };
    };
    qcom,pm7250b@3 {
        #address-cells = <0x1>;
        #size-cells = <0x0>;
        compatible = "qcom,spmi-pmic";
        reg = <0x3 0x0>;
        pm7250b_vib: qcom,vibrator@5300 {
            compatible = "qcom,qpnp-vibrator-ldo";
            qcom,disable-overdrive;
            qcom,vib-ldo-volt-uv = <0x2DC6C0>;
            reg = <0x5300>;
        };
    };
};

&thermal_zones {
    charger-therm-usr {
        polling-delay = <0x0>;
        polling-delay-passive = <0x0>;
        thermal-governor = "user_space";
        thermal-sensors = <&pm7250b_adc_tm 0x0>;
        wake-capable-sensor;
        trips {
            active-config0 {
                hysteresis = <0x3E8>;
                temperature = <0x1E848>;
                type = "passive";
            };
        };
    };
    conn-therm-usr {
        polling-delay = <0x0>;
        polling-delay-passive = <0x0>;
        thermal-governor = "user_space";
        thermal-sensors = <&pm7250b_adc_tm 0x1>;
        wake-capable-sensor;
        trips {
            active-config0 {
                hysteresis = <0x3E8>;
                temperature = <0x1E848>;
                type = "passive";
            };
        };
    };
    pm6125-tz {
        cooling-maps {
            trip0_cpu0 {
                cooling-device = <&CPU0 0x7 0x7>;
                trip = <&pm6125_trip0>;
            };
            trip0_cpu4 {
                cooling-device = <&CPU4 0x6 0xFFFFFFFF>;
                trip = <&pm6125_trip0>;
            };
            trip1_cpu1 {
                cooling-device = <&cpu1_pause 0x1 0x1>;
                trip = <&pm6125_trip1>;
            };
            trip1_cpu2 {
                cooling-device = <&cpu2_pause 0x1 0x1>;
                trip = <&pm6125_trip1>;
            };
            trip1_cpu3 {
                cooling-device = <&cpu3_pause 0x1 0x1>;
                trip = <&pm6125_trip1>;
            };
            trip1_cpu4 {
                cooling-device = <&cpu4_pause 0x1 0x1>;
                trip = <&pm6125_trip1>;
            };
            trip1_cpu5 {
                cooling-device = <&cpu5_pause 0x1 0x1>;
                trip = <&pm6125_trip1>;
            };
            trip1_cpu6 {
                cooling-device = <&cpu6_pause 0x1 0x1>;
                trip = <&pm6125_trip1>;
            };
            trip1_cpu7 {
                cooling-device = <&cpu7_pause 0x1 0x1>;
                trip = <&pm6125_trip1>;
            };
        };
    };
    pm7250b-bcl-lvl0 {
        polling-delay = <0x0>;
        polling-delay-passive = <0x64>;
        thermal-sensors = <&pm7250b_bcl 0x5>;
        trips {
            b-bcl-lvl0 {
                hysteresis = <0x1>;
                temperature = <0x1>;
                type = "passive";
            };
        };
        cooling-maps {
            lbat0_cdsp {
                cooling-device = <&cdsp_sw 0x2 0x2>;
                trip = <&b_bcl_lvl0>;
            };
            lbat0_cpu6 {
                cooling-device = <&cpu6_pause 0x1 0x1>;
                trip = <&b_bcl_lvl0>;
            };
            lbat0_cpu7 {
                cooling-device = <&cpu7_pause 0x1 0x1>;
                trip = <&b_bcl_lvl0>;
            };
            lbat0_cpufreq4 {
                cooling-device = <&CPU4 0x2 0x2>;
                trip = <&b_bcl_lvl0>;
            };
            lbat0_gpu {
                cooling-device = <&msm_gpu 0x2 0x2>;
                trip = <&b_bcl_lvl0>;
            };
        };
    };
    pm7250b-bcl-lvl1 {
        polling-delay = <0x0>;
        polling-delay-passive = <0x64>;
        thermal-sensors = <&pm7250b_bcl 0x6>;
        trips {
            b-bcl-lvl1 {
                hysteresis = <0x1>;
                temperature = <0x1>;
                type = "passive";
            };
        };
        cooling-maps {
            lbat1_cdsp {
                cooling-device = <&cdsp_sw 0x4 0x4>;
                trip = <&b_bcl_lvl1>;
            };
            lbat1_cpu4 {
                cooling-device = <&cpu4_pause 0x1 0x1>;
                trip = <&b_bcl_lvl1>;
            };
            lbat1_cpu5 {
                cooling-device = <&cpu5_pause 0x1 0x1>;
                trip = <&b_bcl_lvl1>;
            };
            lbat1_gpu {
                cooling-device = <&msm_gpu 0x4 0x4>;
                trip = <&b_bcl_lvl1>;
            };
        };
    };
    pm7250b-bcl-lvl2 {
        polling-delay = <0x0>;
        polling-delay-passive = <0x64>;
        thermal-sensors = <&pm7250b_bcl 0x7>;
        trips {
            b-bcl-lvl2 {
                hysteresis = <0x1>;
                temperature = <0x1>;
                type = "passive";
            };
        };
        cooling-maps {
            lbat2_cdsp {
                cooling-device = <&cdsp_sw 0x4 0x4>;
                trip = <&b_bcl_lvl2>;
            };
            lbat2_gpu {
                cooling-device = <&msm_gpu 0x4 0xFFFFFFFF>;
                trip = <&b_bcl_lvl2>;
            };
        };
    };
    pm7250b-ibat-lvl0 {
        polling-delay = <0x0>;
        polling-delay-passive = <0x0>;
        thermal-sensors = <&pm7250b_bcl 0x0>;
        trips {
            ibat-lvl0 {
                hysteresis = <0xC8>;
                temperature = <0x157C>;
                type = "passive";
            };
        };
    };
    pm7250b-ibat-lvl1 {
        polling-delay = <0x0>;
        polling-delay-passive = <0x0>;
        thermal-sensors = <&pm7250b_bcl 0x1>;
        trips {
            ibat-lvl1 {
                hysteresis = <0xC8>;
                temperature = <0x1770>;
                type = "passive";
            };
        };
    };
    pm7250b-tz {
        polling-delay = <0x0>;
        polling-delay-passive = <0x64>;
        thermal-sensors = <&pm7250b_tz>;
        trips {
            trip0 {
                hysteresis = <0x0>;
                temperature = <0x17318>;
                type = "passive";
            };
            trip1 {
                hysteresis = <0x0>;
                temperature = <0x1C138>;
                type = "passive";
            };
            trip2 {
                hysteresis = <0x0>;
                temperature = <0x23668>;
                type = "passive";
            };
        };
        cooling-maps {
            trip0_bat {
                cooling-device = <&pm7250b_charger 0x9 0x9>;
                trip = <&pm7250b_trip0>;
            };
            trip1_bat {
                cooling-device = <&pm7250b_charger 0xA 0xA>;
                trip = <&pm7250b_trip1>;
            };
        };
    };
    rf-pa1-therm-usr {
        polling-delay = <0x0>;
        polling-delay-passive = <0x0>;
        thermal-governor = "user_space";
        thermal-sensors = <&pm6125_adc_tm 0x3>;
        wake-capable-sensor;
        trips {
            active-config0 {
                hysteresis = <0x3E8>;
                temperature = <0x1E848>;
                type = "passive";
            };
        };
    };
    socd {
        polling-delay = <0x0>;
        polling-delay-passive = <0x64>;
        thermal-sensors = <&bcl_soc>;
        trips {
            soc-trip {
                hysteresis = <0x0>;
                temperature = <0x5A>;
                type = "passive";
            };
            thermal-engine-trip {
                hysteresis = <0x0>;
                temperature = <0x64>;
                type = "passive";
            };
            thermal-hal-trip {
                hysteresis = <0x0>;
                temperature = <0x64>;
                type = "passive";
            };
        };
        cooling-maps {
            soc_cpu4 {
                cooling-device = <&cpu4_pause 0x1 0x1>;
                trip = <&soc_trip>;
            };
            soc_cpu5 {
                cooling-device = <&cpu5_pause 0x1 0x1>;
                trip = <&soc_trip>;
            };
            soc_cpu6 {
                cooling-device = <&cpu6_pause 0x1 0x1>;
                trip = <&soc_trip>;
            };
            soc_cpu7 {
                cooling-device = <&cpu7_pause 0x1 0x1>;
                trip = <&soc_trip>;
            };
        };
    };
};

&ufshc_mem {
    qcom,vddp-ref-clk-max-microamp = <0x64>;
    qcom,vddp-ref-clk-supply = <&L18A>;
    reset-gpios = <&tlmm 0x71 0x1>;
    reset-names = "rst";
    resets = <&gcc 0x4>;
    status = "ok";
    vcc-max-microamp = <0xC3500>;
    vcc-supply = <&L24A>;
    vccq2-max-microamp = <0xC3500>;
    vccq2-supply = <&L11A>;
    vdd-hba-fixed-regulator;
    vdd-hba-supply = <&gcc_ufs_phy_gdsc>;
};

&ufsphy_mem {
    compatible = "qcom,ufs-phy-qmp-v4-khaje";
    status = "ok";
    vdda-phy-max-microamp = <0x14EC4>;
    vdda-phy-supply = <&L4A>;
    vdda-pll-max-microamp = <0x477C>;
    vdda-pll-supply = <&L18A>;
};

&usb0 {
    extcon = <&pm7250b_pdphy &pm7250b_charger &eud>;
};

&usb_qmp_dp_phy {
    vdd-supply = <&vdda_usb_ss_dp_core>;
};

